[part 1 of 2: packages /EcuInstances to /Communication/TpConfig]
AUTOSAR XML (schema 4-2-2)
package /EcuInstances
  ecu instance IEM: associated-com-i-pdu-group=[TxMPG_PropulsionCAN, RxMPG_PropulsionCAN], com-configuration-gw-time-base=0.005, com-configuration-rx-time-base=0.005, com-configuration-tx-time-base=0.005, sleep-mode-supported=true, wake-up-over-bus-supported=true  # Inverter Electric rear axle drive Module
    can communication controller PropulsionCAN: wake-up-by-controller-supported=true, can-controller-attributes=can-controller-configuration-requirements={max-number-of-time-quanta-per-bit=22, max-sample-point=86.67, max-sync-jump-width=13, min-number-of-time-quanta-per-bit=10, min-sample-point=80, min-sync-jump-width=9}
    can communication connector PropulsionCAN_IEM: comm-controller=PropulsionCAN, pnc-gateway-type=NONE, pnc-wakeup-data-mask=594567823360
package /CommunicationClusters
  can cluster PropulsionCAN: baudrate=500000, protocol-name=CAN, protocol-version=CAN
    can physical channel PropulsionCAN: comm-connectors=PropulsionCAN_IEM
      frame IemToVddmPropDiagResFrame: id 0x637, from IEM, frame-length=8, can-addressing-mode=STANDARD, can-fd-frame-support=false, can-frame-tx-behavior=CAN-20
        n pdu IemToVddmPropDiagResNpdu: length=8
      frame IemPropNMFr: id 0x51C, from IEM, frame-length=8, can-addressing-mode=STANDARD, can-fd-frame-support=false, can-frame-tx-behavior=CAN-20
        nm pdu IemPropNmPdu1: length=8, nm-vote-information=false, unused-bit-pattern=0
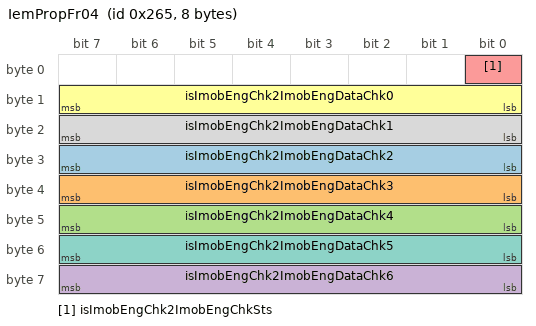
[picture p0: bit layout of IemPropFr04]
      frame IemPropFr04: id 0x265, from IEM, frame-length=8, can-addressing-mode=STANDARD, can-fd-frame-support=false, can-frame-tx-behavior=CAN-20
        pdu IemPropSignalIPdu04: length=8, transmission-mode-condition{data-filter=data-filter-type=ALWAYS, i-signal-in-i-pdu=isImobEngChk2ImobEngChkSts_mtx}, transmission-mode-true-timing=cyclic-timing={time-offset=0, time-period=0.08}, unused-bit-pattern=0
          signal isImobEngChk2ImobEngDataChk2: start 31, 8 bit, big-endian, data-type-policy=NETWORK-REPRESENTATION-FROM-COM-SPEC, init-value=0, base-type=UInt8_2, compu {identical; unit Unitless}, category=VALUE  # Message from IEM to CEM that challenge is available and 7 bytes of challenge. Byte 2
          signal isImobEngChk2ImobEngDataChk3: start 39, 8 bit, big-endian, data-type-policy=NETWORK-REPRESENTATION-FROM-COM-SPEC, init-value=0, base-type=UInt8_2, compu {identical; unit Unitless}, category=VALUE  # Message from IEM to CEM that challenge is available and 7 bytes of challenge. Byte 3
          signal isImobEngChk2ImobEngDataChk4: start 47, 8 bit, big-endian, data-type-policy=NETWORK-REPRESENTATION-FROM-COM-SPEC, init-value=0, base-type=UInt8_2, compu {identical; unit Unitless}, category=VALUE  # Message from IEM to CEM that challenge is available and 7 bytes of challenge. Byte 4
          signal isImobEngChk2ImobEngDataChk6: start 63, 8 bit, big-endian, data-type-policy=NETWORK-REPRESENTATION-FROM-COM-SPEC, init-value=0, base-type=UInt8_2, compu {identical; unit Unitless}, category=VALUE  # Message from IEM to CEM that challenge is available and 7 bytes of challenge. Byte 6
          signal isImobEngChk2ImobEngChkSts: start 0, 1 bit, big-endian, data-type-policy=NETWORK-REPRESENTATION-FROM-COM-SPEC, init-value=0, base-type=AvlSts2_2, compu {0=AvlSts2_NotAvl, 1=AvlSts2_Avl; unit Unitless}, category=VALUE  # Message from IEM to CEM that challenge is available and 7 bytes of challenge. Message to CEM Challenge available
          signal isImobEngChk2ImobEngDataChk0: start 15, 8 bit, big-endian, data-type-policy=NETWORK-REPRESENTATION-FROM-COM-SPEC, init-value=0, base-type=UInt8_2, compu {identical; unit Unitless}, category=VALUE  # Message from IEM to CEM that challenge is available and 7 bytes of challenge. Byte 0
          signal isImobEngChk2ImobEngDataChk5: start 55, 8 bit, big-endian, data-type-policy=NETWORK-REPRESENTATION-FROM-COM-SPEC, init-value=0, base-type=UInt8_2, compu {identical; unit Unitless}, category=VALUE  # Message from IEM to CEM that challenge is available and 7 bytes of challenge. Byte 5
          signal isImobEngChk2ImobEngDataChk1: start 23, 8 bit, big-endian, data-type-policy=NETWORK-REPRESENTATION-FROM-COM-SPEC, init-value=0, base-type=UInt8_2, compu {identical; unit Unitless}, category=VALUE  # Message from IEM to CEM that challenge is available and 7 bytes of challenge. Byte 1
          mapping igImobEngChk2_mtx: i-signal-group=igImobEngChk2, packing-byte-order=big-endian, start-position=0, transfer-property=PENDING, update-indication-bit-position=1
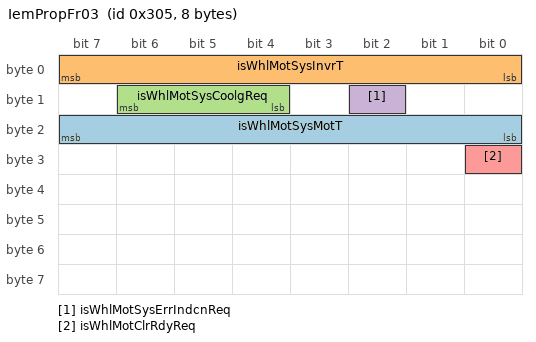
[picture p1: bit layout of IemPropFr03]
      frame IemPropFr03: id 0x305, from IEM, frame-length=8, can-addressing-mode=STANDARD, can-fd-frame-support=false, can-frame-tx-behavior=CAN-20
        pdu IemPropSignalIPdu03: length=8, transmission-mode-condition{data-filter=data-filter-type=ALWAYS, i-signal-in-i-pdu=isWhlMotSysInvrT_mtx}, transmission-mode-true-timing=cyclic-timing={time-offset=0, time-period=0.6}, unused-bit-pattern=0
          signal isWhlMotSysMotT: start 23, 8 bit, big-endian, data-type-policy=NETWORK-REPRESENTATION-FROM-COM-SPEC, init-value=50, base-type=T3_2, compu {phys=raw-50 for raw 0..250; unit degC}, transfer-property=PENDING, update-indication-bit-position=8  # The temperature of motor
          signal isWhlMotSysInvrT: start 7, 8 bit, big-endian, data-type-policy=NETWORK-REPRESENTATION-FROM-COM-SPEC, init-value=50, base-type=T3_2, compu {phys=raw-50 for raw 0..250; unit degC}, transfer-property=PENDING, update-indication-bit-position=15  # The inverter temperature measured in the IEM.
          signal isWhlMotSysCoolgReq: start 14, 3 bit, big-endian, data-type-policy=NETWORK-REPRESENTATION-FROM-COM-SPEC, init-value=0, base-type=HvCoolg1_2, compu-method=HvCoolg1_1, transfer-property=PENDING, update-indication-bit-position=11  # Signal to request increased cooling to Erad and IEM.Request is in 3 steps of increased cooling.
          signal isWhlMotSysErrIndcnReq: start 10, 1 bit, big-endian, data-type-policy=NETWORK-REPRESENTATION-FROM-COM-SPEC, init-value=0, base-type=OnOff1_2, compu {0=OnOff1_Off, 1=OnOff1_On; unit Unitless}, transfer-property=PENDING, update-indication-bit-position=9
          signal isWhlMotClrRdyReq: start 24, 1 bit, big-endian, data-type-policy=NETWORK-REPRESENTATION-FROM-COM-SPEC, init-value=0, base-type=OnOff1_2, compu {0=OnOff1_Off, 1=OnOff1_On; unit Unitless}, transfer-property=PENDING, update-indication-bit-position=25
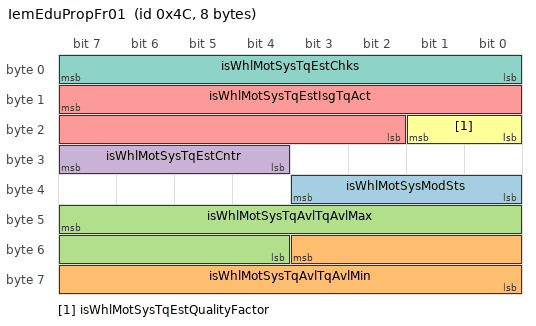
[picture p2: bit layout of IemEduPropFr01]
      frame IemEduPropFr01: id 0x4C, from IEM, frame-length=8, can-addressing-mode=STANDARD, can-fd-frame-support=false, can-frame-tx-behavior=CAN-20
        pdu IemEduPropSignalIPdu01: length=8, transmission-mode-condition{data-filter=data-filter-type=ALWAYS, i-signal-in-i-pdu=isWhlMotSysTqEstChks_mtx}, transmission-mode-true-timing=cyclic-timing={time-offset=0, time-period=0.01}, unused-bit-pattern=0
          signal isWhlMotSysModSts: start 35, 4 bit, big-endian, data-type-policy=NETWORK-REPRESENTATION-FROM-COM-SPEC, init-value=0, base-type=WhlMotSysModStsTyp2_2, compu-method=WhlMotSysModStsTyp2_2, transfer-property=PENDING, update-indication-bit-position=36  # Reflects the current operating mode of the IEM.
          signal isWhlMotSysTqAvlTqAvlMin: start 51, 12 bit, big-endian, data-type-policy=NETWORK-REPRESENTATION-FROM-COM-SPEC, init-value=2047, base-type=HvTq1_2, compu {phys=raw*4-8188 for raw 0..4095; unit NewtonMeter}, category=VALUE  # Min available torque
          signal isWhlMotSysTqAvlTqAvlMax: start 47, 12 bit, big-endian, data-type-policy=NETWORK-REPRESENTATION-FROM-COM-SPEC, init-value=2047, base-type=HvTq1_2, compu {phys=raw*4-8188 for raw 0..4095; unit NewtonMeter}, category=VALUE  # Max available torque
          mapping igWhlMotSysTqAvl_mtx: i-signal-group=igWhlMotSysTqAvl, packing-byte-order=big-endian, start-position=47, transfer-property=PENDING, update-indication-bit-position=37
          signal isWhlMotSysTqEstCntr: start 31, 4 bit, big-endian, data-type-policy=NETWORK-REPRESENTATION-FROM-COM-SPEC, init-value=0, base-type=UInt4_2, compu {identical; unit Unitless}, category=VALUE  # Counter of estimation torque
          signal isWhlMotSysTqEstIsgTqAct: start 15, 14 bit, big-endian, data-type-policy=NETWORK-REPRESENTATION-FROM-COM-SPEC, init-value=8188, base-type=Tq34_1, compu {phys=raw-8188 for raw 0..16380; unit NewtonMeter}, category=VALUE  # Estimation torque of Rear Axle Control
          signal isWhlMotSysTqEstQualityFactor: start 17, 2 bit, big-endian, data-type-policy=NETWORK-REPRESENTATION-FROM-COM-SPEC, init-value=1, base-type=QualityFactor_2, compu-method=QualityFactor_1, category=VALUE  # Quality factor of estimation torque
          signal isWhlMotSysTqEstChks: start 7, 8 bit, big-endian, data-type-policy=NETWORK-REPRESENTATION-FROM-COM-SPEC, init-value=0, base-type=UInt8_2, compu {identical; unit Unitless}, category=VALUE  # Checksum of estimation torque
          mapping igWhlMotSysTqEst_mtx: i-signal-group=igWhlMotSysTqEst, packing-byte-order=big-endian, start-position=7, transfer-property=PENDING, update-indication-bit-position=27
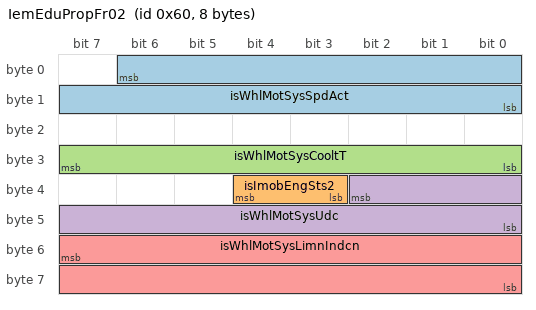
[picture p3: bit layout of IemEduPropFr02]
      frame IemEduPropFr02: id 0x60, from IEM, frame-length=8, can-addressing-mode=STANDARD, can-fd-frame-support=false, can-frame-tx-behavior=CAN-20
        pdu IemEduPropSignalIPdu02: length=8, transmission-mode-condition{data-filter=data-filter-type=ALWAYS, i-signal-in-i-pdu=isWhlMotSysSpdAct_mtx}, transmission-mode-true-timing=cyclic-timing={time-offset=0, time-period=0.02}, unused-bit-pattern=0
          signal isWhlMotSysSpdAct: start 6, 15 bit, big-endian, data-type-policy=NETWORK-REPRESENTATION-FROM-COM-SPEC, init-value=0, base-type=IsgSpdWSgnTyp_2, compu {phys=raw for raw -16384..16383; unit rpm}, transfer-property=PENDING, update-indication-bit-position=7  # The actual rotational speed of rear motor
          signal isImobEngSts2: start 36, 2 bit, big-endian, data-type-policy=NETWORK-REPRESENTATION-FROM-COM-SPEC, init-value=0, base-type=ImobSts_2, compu-method=ImobSts_1, transfer-property=PENDING, update-indication-bit-position=37  # IEM CEM message immo status. Can be undefined, immobilised, motive mobilised or non motive mobilised.
          signal isWhlMotSysCooltT: start 31, 8 bit, big-endian, data-type-policy=NETWORK-REPRESENTATION-FROM-COM-SPEC, init-value=40, base-type=HvT1_3, compu {phys=raw-40 for raw 0..255; unit degC}, transfer-property=PENDING, update-indication-bit-position=16  # Measured coolant temperature in rear axle inverter in degC
          signal isWhlMotSysUdc: start 34, 11 bit, big-endian, data-type-policy=NETWORK-REPRESENTATION-FROM-COM-SPEC, init-value=0, base-type=HvU1_2, compu {phys=raw*0.25 for raw 0..2044; unit Volt}, transfer-property=PENDING, update-indication-bit-position=38  # The DC voltage of rear motor
          signal isWhlMotSysLimnIndcn: start 55, 16 bit, big-endian, data-type-policy=NETWORK-REPRESENTATION-FROM-COM-SPEC, init-value=0, base-type=UInt16_2, compu {identical; unit Unitless}, transfer-property=PENDING, update-indication-bit-position=39  # The limitation indication of derating conditions
      frame IemToVgmJ1979OBDPropCanResFrame11: id 0x7EB, from IEM, frame-length=8, can-addressing-mode=STANDARD, can-fd-frame-support=false, can-frame-tx-behavior=CAN-20
        n pdu IemToVgmJ1979OBDPropCanResNpdu11: length=8
      frame UudtIemFr01: id 0x6F0, from IEM, frame-length=8, can-addressing-mode=STANDARD, can-fd-frame-support=false, can-frame-tx-behavior=CAN-20
        n pdu UudtIemNPdu1: length=8
      frame UudtIemFr02: id 0x6F1, from IEM, frame-length=8, can-addressing-mode=STANDARD, can-fd-frame-support=false, can-frame-tx-behavior=CAN-20
        n pdu UudtIemNPdu2: length=8
      frame UudtIemFr03: id 0x6F2, from IEM, frame-length=8, can-addressing-mode=STANDARD, can-fd-frame-support=false, can-frame-tx-behavior=CAN-20
        n pdu UudtIemNPdu3: length=8
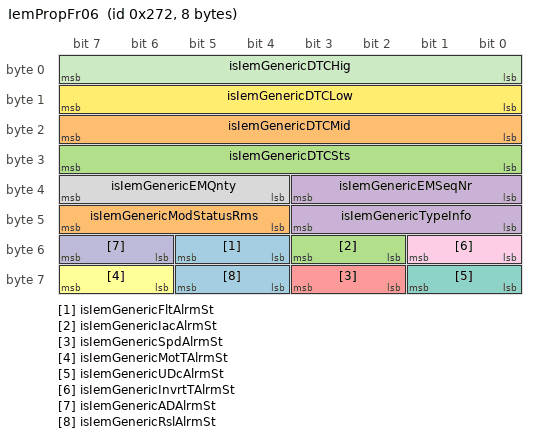
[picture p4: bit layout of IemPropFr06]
      frame IemPropFr06: id 0x272, from IEM, frame-length=8, can-addressing-mode=STANDARD, can-fd-frame-support=false, can-frame-tx-behavior=CAN-20
        pdu IemPropSignalIPdu06: length=8, transmission-mode-condition{data-filter=data-filter-type=ALWAYS, i-signal-in-i-pdu=isIemGenericDTCHig_mtx}, transmission-mode-true-timing=cyclic-timing={time-offset=0, time-period=0.1}, unused-bit-pattern=0
          signal isIemGenericFltAlrmSt: start 53, 2 bit, big-endian, data-type-policy=NETWORK-REPRESENTATION-FROM-COM-SPEC, init-value=0, base-type=AlrmSt_2, compu {0=AlrmSt_Disarmd, 1=AlrmSt_Armd, 2=AlrmSt_Actv; unit Unitless}, category=VALUE  # Fault alarm status
          signal isIemGenericModStatusRms: start 47, 4 bit, big-endian, data-type-policy=NETWORK-REPRESENTATION-FROM-COM-SPEC, init-value=3, base-type=ModStatusRms_2, compu-method=ModStatusRms_2, category=VALUE  # Motor status for RMS monitor
          signal isIemGenericIacAlrmSt: start 51, 2 bit, big-endian, data-type-policy=NETWORK-REPRESENTATION-FROM-COM-SPEC, init-value=0, base-type=AlrmSt_2, compu {0=AlrmSt_Disarmd, 1=AlrmSt_Armd, 2=AlrmSt_Actv; unit Unitless}, category=VALUE  # 3 Phase current alarm status
          signal isIemGenericEMSeqNr: start 35, 4 bit, big-endian, data-type-policy=NETWORK-REPRESENTATION-FROM-COM-SPEC, init-value=0, base-type=UInt4_2, compu {identical; unit Unitless}, category=VALUE  # Sequence number of electric motor
          signal isIemGenericSpdAlrmSt: start 59, 2 bit, big-endian, data-type-policy=NETWORK-REPRESENTATION-FROM-COM-SPEC, init-value=0, base-type=AlrmSt_2, compu {0=AlrmSt_Disarmd, 1=AlrmSt_Armd, 2=AlrmSt_Actv; unit Unitless}, category=VALUE  # Over speed alarm status
          signal isIemGenericMotTAlrmSt: start 63, 2 bit, big-endian, data-type-policy=NETWORK-REPRESENTATION-FROM-COM-SPEC, init-value=0, base-type=AlrmSt_2, compu {0=AlrmSt_Disarmd, 1=AlrmSt_Armd, 2=AlrmSt_Actv; unit Unitless}, category=VALUE  # Motor temperature alarm status
          signal isIemGenericUDcAlrmSt: start 57, 2 bit, big-endian, data-type-policy=NETWORK-REPRESENTATION-FROM-COM-SPEC, init-value=0, base-type=AlrmSt_2, compu {0=AlrmSt_Disarmd, 1=AlrmSt_Armd, 2=AlrmSt_Actv; unit Unitless}, category=VALUE  # High voltage alarm status
          signal isIemGenericEMQnty: start 39, 4 bit, big-endian, data-type-policy=NETWORK-REPRESENTATION-FROM-COM-SPEC, init-value=0, base-type=UInt4_2, compu {identical; unit Unitless}, category=VALUE  # Quantity of electric motor
          signal isIemGenericInvrtTAlrmSt: start 49, 2 bit, big-endian, data-type-policy=NETWORK-REPRESENTATION-FROM-COM-SPEC, init-value=0, base-type=AlrmSt_2, compu {0=AlrmSt_Disarmd, 1=AlrmSt_Armd, 2=AlrmSt_Actv; unit Unitless}, category=VALUE  # Inverter temperature alarm status
          signal isIemGenericADAlrmSt: start 55, 2 bit, big-endian, data-type-policy=NETWORK-REPRESENTATION-FROM-COM-SPEC, init-value=0, base-type=AlrmSt_2, compu {0=AlrmSt_Disarmd, 1=AlrmSt_Armd, 2=AlrmSt_Actv; unit Unitless}, category=VALUE  # Active Discharge fault alarm status
          signal isIemGenericDTCHig: start 7, 8 bit, big-endian, data-type-policy=NETWORK-REPRESENTATION-FROM-COM-SPEC, init-value=0, base-type=UInt8_2, compu {identical; unit Unitless}, category=VALUE  # DTC high byte for non OBD or OBD
          signal isIemGenericDTCLow: start 15, 8 bit, big-endian, data-type-policy=NETWORK-REPRESENTATION-FROM-COM-SPEC, init-value=0, base-type=UInt8_2, compu {identical; unit Unitless}, category=VALUE  # DTC low byte for non OBD
          signal isIemGenericRslAlrmSt: start 61, 2 bit, big-endian, data-type-policy=NETWORK-REPRESENTATION-FROM-COM-SPEC, init-value=0, base-type=AlrmSt_2, compu {0=AlrmSt_Disarmd, 1=AlrmSt_Armd, 2=AlrmSt_Actv; unit Unitless}, category=VALUE  # Resolver fault alarm status
          signal isIemGenericDTCMid: start 23, 8 bit, big-endian, data-type-policy=NETWORK-REPRESENTATION-FROM-COM-SPEC, init-value=0, base-type=UInt8_2, compu {identical; unit Unitless}, category=VALUE  # DTC middle byte for non OBD DTC low byte for OBD
          signal isIemGenericDTCSts: start 31, 8 bit, big-endian, data-type-policy=NETWORK-REPRESENTATION-FROM-COM-SPEC, init-value=0, base-type=UInt8_2, compu {identical; unit Unitless}, category=VALUE  # DTC Status
          signal isIemGenericTypeInfo: start 43, 4 bit, big-endian, data-type-policy=NETWORK-REPRESENTATION-FROM-COM-SPEC, init-value=0, base-type=UInt4_2, compu {identical; unit Unitless}, category=VALUE  # Indicate different EDS suppliers. OEM defines this value. 0=not defined 1=PMA1 VseA, with ratio=10.134 2=PMA1 Nidec,with ratio=10.294 3=PMA1 VREMT,with ratio=11.56 4=SPAL Scheaffler,with ratio=9.071 5=SPA Simens, with ratio=10.008 6=PMA2 VREMT,with ratio=11.209 7=EPA ZF,with radio=9.187 8=EPA Polestar,with 2-gear ratio=7.155 and 13.645 9=PMA2 UAES,with ratio=11.067
          mapping igIemGeneric_mtx: i-signal-group=igIemGeneric, packing-byte-order=big-endian, start-position=7, transfer-property=PENDING
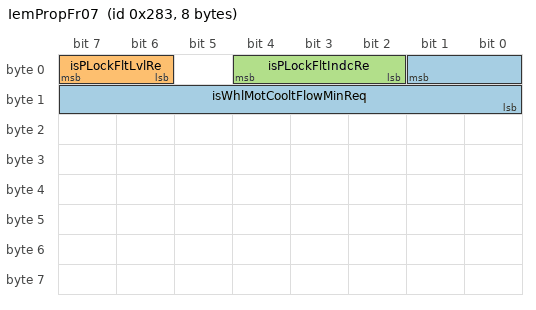
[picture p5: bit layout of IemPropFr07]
      frame IemPropFr07: id 0x283, from IEM, frame-length=8, can-addressing-mode=STANDARD, can-fd-frame-support=false, can-frame-tx-behavior=CAN-20
        pdu IemPropSignalIPdu07: length=8, transmission-mode-condition{data-filter=data-filter-type=ALWAYS, i-signal-in-i-pdu=isWhlMotCooltFlowMinReq_mtx}, transmission-mode-true-timing=cyclic-timing={time-offset=0, time-period=0.15}, unused-bit-pattern=0
          signal isWhlMotCooltFlowMinReq: start 1, 10 bit, big-endian, data-type-policy=NETWORK-REPRESENTATION-FROM-COM-SPEC, init-value=0, base-type=CooltFlowForDtElec1_2, compu {phys=raw*0.01 for raw 0..1023; unit L / min}, transfer-property=PENDING, update-indication-bit-position=54  # Minimum coolant flow required by rear wheel motor
          signal isPLockFltLvlRe: start 7, 2 bit, big-endian, data-type-policy=NETWORK-REPRESENTATION-FROM-COM-SPEC, init-value=0, base-type=FltLvl_1, compu {0=FltLvl_NoFlt, 1=FltLvl_FltLvl1, 2=FltLvl_FltLvl2; unit Unitless}, transfer-property=PENDING, update-indication-bit-position=55  # P-lock fault level, for rear electric drive.
          signal isPLockFltIndcRe: start 4, 3 bit, big-endian, data-type-policy=NETWORK-REPRESENTATION-FROM-COM-SPEC, init-value=0, base-type=FltIndcn_1, compu-method=FltIndcn_1, transfer-property=PENDING, update-indication-bit-position=5  # Fault indication signal for P-lock, for rear electric drive
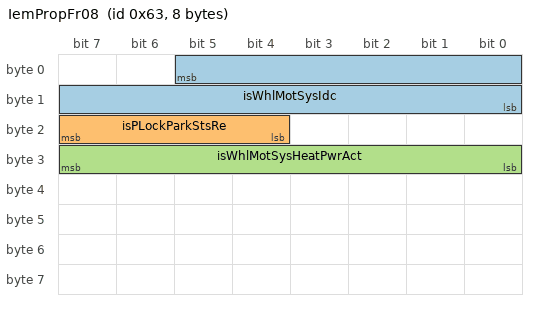
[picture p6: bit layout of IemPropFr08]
      frame IemPropFr08: id 0x63, from IEM, frame-length=8, can-addressing-mode=STANDARD, can-fd-frame-support=false, can-frame-tx-behavior=CAN-20
        pdu IemPropSignalIPdu08: length=8, transmission-mode-condition{data-filter=data-filter-type=ALWAYS, i-signal-in-i-pdu=isWhlMotSysIdc_mtx}, transmission-mode-true-timing=cyclic-timing={time-offset=0, time-period=0.02}, unused-bit-pattern=0
          signal isWhlMotSysIdc: start 5, 14 bit, big-endian, data-type-policy=NETWORK-REPRESENTATION-FROM-COM-SPEC, init-value=8188, base-type=Ampr1_1, compu {phys=raw*0.1-818.8 for raw 0..16380; unit A}, transfer-property=PENDING, update-indication-bit-position=6  # DC current measured in the IEM.
          signal isPLockParkStsRe: start 23, 4 bit, big-endian, data-type-policy=NETWORK-REPRESENTATION-FROM-COM-SPEC, init-value=7, base-type=ParkSts_1, compu-method=ParkSts_1, transfer-property=PENDING, update-indication-bit-position=7  # P-lock status (IEM)
          signal isWhlMotSysHeatPwrAct: start 31, 8 bit, big-endian, data-type-policy=NETWORK-REPRESENTATION-FROM-COM-SPEC, init-value=0, base-type=IsgHeatPwr_1, compu {phys=raw*50 for raw 0..255; unit W}, transfer-property=PENDING, update-indication-bit-position=19  # The actual electrical energy consumption for active heating of rear motor
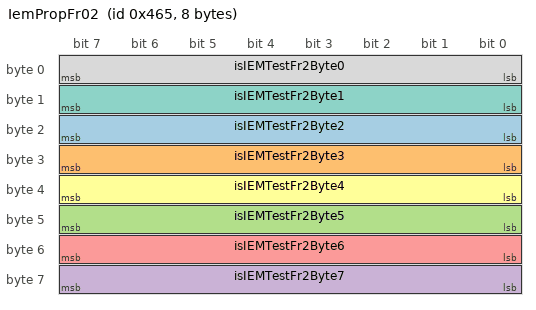
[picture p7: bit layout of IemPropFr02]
      frame IemPropFr02: id 0x465, from IEM, frame-length=8, can-addressing-mode=STANDARD, can-fd-frame-support=false, can-frame-tx-behavior=CAN-20
        pdu IemPropSignalIPdu02: length=8, transmission-mode-condition{data-filter=data-filter-type=ALWAYS, i-signal-in-i-pdu=isIEMTestFr2Byte0_mtx}, transmission-mode-true-timing=cyclic-timing={time-offset=0, time-period=0.8}, unused-bit-pattern=0
          signal isIEMTestFr2Byte2: start 23, 8 bit, big-endian, data-type-policy=NETWORK-REPRESENTATION-FROM-COM-SPEC, init-value=0, base-type=UInt8_2, compu {identical; unit Unitless}, category=VALUE  # DTC1 middle byte
          signal isIEMTestFr2Byte3: start 31, 8 bit, big-endian, data-type-policy=NETWORK-REPRESENTATION-FROM-COM-SPEC, init-value=0, base-type=UInt8_2, compu {identical; unit Unitless}, category=VALUE  # DTC1 high byte
          signal isIEMTestFr2Byte5: start 47, 8 bit, big-endian, data-type-policy=NETWORK-REPRESENTATION-FROM-COM-SPEC, init-value=0, base-type=UInt8_2, compu {identical; unit Unitless}, category=VALUE  # DTC2 low byte
          signal isIEMTestFr2Byte7: start 63, 8 bit, big-endian, data-type-policy=NETWORK-REPRESENTATION-FROM-COM-SPEC, init-value=0, base-type=UInt8_2, compu {identical; unit Unitless}, category=VALUE  # DTC2 high byte
          signal isIEMTestFr2Byte6: start 55, 8 bit, big-endian, data-type-policy=NETWORK-REPRESENTATION-FROM-COM-SPEC, init-value=0, base-type=UInt8_2, compu {identical; unit Unitless}, category=VALUE  # DTC2 middle byte
          signal isIEMTestFr2Byte4: start 39, 8 bit, big-endian, data-type-policy=NETWORK-REPRESENTATION-FROM-COM-SPEC, init-value=0, base-type=UInt8_2, compu {identical; unit Unitless}, category=VALUE  # DTC2 status
          signal isIEMTestFr2Byte1: start 15, 8 bit, big-endian, data-type-policy=NETWORK-REPRESENTATION-FROM-COM-SPEC, init-value=0, base-type=UInt8_2, compu {identical; unit Unitless}, category=VALUE  # DTC1 low byte
          signal isIEMTestFr2Byte0: start 7, 8 bit, big-endian, data-type-policy=NETWORK-REPRESENTATION-FROM-COM-SPEC, init-value=0, base-type=UInt8_2, compu {identical; unit Unitless}, category=VALUE  # DTC1 status
          mapping igIEMTestFr2_mtx: i-signal-group=igIEMTestFr2, packing-byte-order=big-endian, start-position=7, transfer-property=TRIGGERED
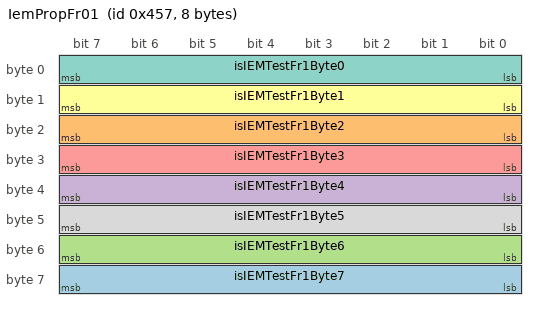
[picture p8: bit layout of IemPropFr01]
      frame IemPropFr01: id 0x457, from IEM, frame-length=8, can-addressing-mode=STANDARD, can-fd-frame-support=false, can-frame-tx-behavior=CAN-20
        pdu IemPropSignalIPdu01: length=8, transmission-mode-condition{data-filter=data-filter-type=ALWAYS, i-signal-in-i-pdu=isIEMTestFr1Byte0_mtx}, transmission-mode-true-timing=cyclic-timing={time-offset=0, time-period=0.8}, unused-bit-pattern=0
          signal isIEMTestFr1Byte7: start 63, 8 bit, big-endian, data-type-policy=NETWORK-REPRESENTATION-FROM-COM-SPEC, init-value=0, base-type=UInt8_2, compu {identical; unit Unitless}, category=VALUE  # DTC2 high byte
          signal isIEMTestFr1Byte2: start 23, 8 bit, big-endian, data-type-policy=NETWORK-REPRESENTATION-FROM-COM-SPEC, init-value=0, base-type=UInt8_2, compu {identical; unit Unitless}, category=VALUE  # DTC1 middle byte
          signal isIEMTestFr1Byte6: start 55, 8 bit, big-endian, data-type-policy=NETWORK-REPRESENTATION-FROM-COM-SPEC, init-value=0, base-type=UInt8_2, compu {identical; unit Unitless}, category=VALUE  # DTC2 middle byte
          signal isIEMTestFr1Byte4: start 39, 8 bit, big-endian, data-type-policy=NETWORK-REPRESENTATION-FROM-COM-SPEC, init-value=0, base-type=UInt8_2, compu {identical; unit Unitless}, category=VALUE  # DTC2 status
          signal isIEMTestFr1Byte3: start 31, 8 bit, big-endian, data-type-policy=NETWORK-REPRESENTATION-FROM-COM-SPEC, init-value=0, base-type=UInt8_2, compu {identical; unit Unitless}, category=VALUE  # DTC1 high byte
          signal isIEMTestFr1Byte1: start 15, 8 bit, big-endian, data-type-policy=NETWORK-REPRESENTATION-FROM-COM-SPEC, init-value=0, base-type=UInt8_2, compu {identical; unit Unitless}, category=VALUE  # DTC1 low byte
          signal isIEMTestFr1Byte0: start 7, 8 bit, big-endian, data-type-policy=NETWORK-REPRESENTATION-FROM-COM-SPEC, init-value=0, base-type=UInt8_2, compu {identical; unit Unitless}, category=VALUE  # DTC1 status
          signal isIEMTestFr1Byte5: start 47, 8 bit, big-endian, data-type-policy=NETWORK-REPRESENTATION-FROM-COM-SPEC, init-value=0, base-type=UInt8_2, compu {identical; unit Unitless}, category=VALUE  # DTC2 low byte
          mapping igIEMTestFr1_mtx: i-signal-group=igIEMTestFr1, packing-byte-order=big-endian, start-position=7, transfer-property=TRIGGERED
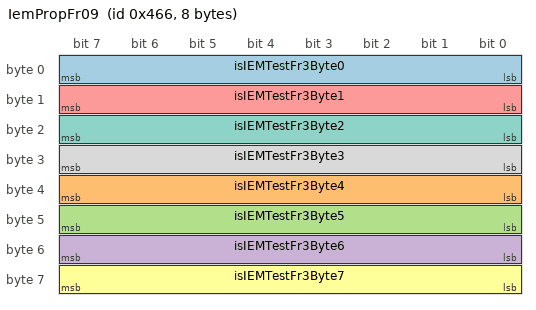
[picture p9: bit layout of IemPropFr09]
      frame IemPropFr09: id 0x466, from IEM, frame-length=8, can-addressing-mode=STANDARD, can-fd-frame-support=false, can-frame-tx-behavior=CAN-20
        pdu IemPropSignalIPdu09: length=8, transmission-mode-condition{data-filter=data-filter-type=ALWAYS, i-signal-in-i-pdu=isIEMTestFr3Byte0_mtx}, transmission-mode-true-timing=cyclic-timing={time-offset=0, time-period=0.8}, unused-bit-pattern=0
          signal isIEMTestFr3Byte0: start 7, 8 bit, big-endian, data-type-policy=NETWORK-REPRESENTATION-FROM-COM-SPEC, init-value=0, base-type=UInt8_2, compu {identical; unit Unitless}, category=VALUE  # Info0
          signal isIEMTestFr3Byte4: start 39, 8 bit, big-endian, data-type-policy=NETWORK-REPRESENTATION-FROM-COM-SPEC, init-value=0, base-type=UInt8_2, compu {identical; unit Unitless}, category=VALUE  # Info4
          signal isIEMTestFr3Byte5: start 47, 8 bit, big-endian, data-type-policy=NETWORK-REPRESENTATION-FROM-COM-SPEC, init-value=0, base-type=UInt8_2, compu {identical; unit Unitless}, category=VALUE  # Info5
          signal isIEMTestFr3Byte6: start 55, 8 bit, big-endian, data-type-policy=NETWORK-REPRESENTATION-FROM-COM-SPEC, init-value=0, base-type=UInt8_2, compu {identical; unit Unitless}, category=VALUE  # Info6
          signal isIEMTestFr3Byte1: start 15, 8 bit, big-endian, data-type-policy=NETWORK-REPRESENTATION-FROM-COM-SPEC, init-value=0, base-type=UInt8_2, compu {identical; unit Unitless}, category=VALUE  # Info1
          signal isIEMTestFr3Byte7: start 63, 8 bit, big-endian, data-type-policy=NETWORK-REPRESENTATION-FROM-COM-SPEC, init-value=0, base-type=UInt8_2, compu {identical; unit Unitless}, category=VALUE  # Info7
          signal isIEMTestFr3Byte2: start 23, 8 bit, big-endian, data-type-policy=NETWORK-REPRESENTATION-FROM-COM-SPEC, init-value=0, base-type=UInt8_2, compu {identical; unit Unitless}, category=VALUE  # Info2
          signal isIEMTestFr3Byte3: start 31, 8 bit, big-endian, data-type-policy=NETWORK-REPRESENTATION-FROM-COM-SPEC, init-value=0, base-type=UInt8_2, compu {identical; unit Unitless}, category=VALUE  # Info3
          mapping igIEMTestFr3_mtx: i-signal-group=igIEMTestFr3, packing-byte-order=big-endian, start-position=7, transfer-property=TRIGGERED
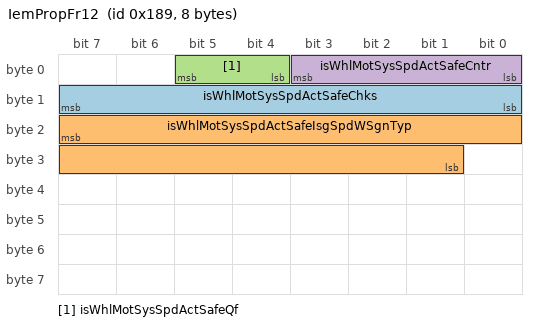
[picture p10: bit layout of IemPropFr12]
      frame IemPropFr12: id 0x189, from IEM, frame-length=8, can-addressing-mode=STANDARD, can-fd-frame-support=false, can-frame-tx-behavior=CAN-20
        pdu IemPropSignalIPdu12: length=8, transmission-mode-condition{data-filter=data-filter-type=ALWAYS, i-signal-in-i-pdu=isWhlMotSysSpdActSafeCntr_mtx}, transmission-mode-true-timing=cyclic-timing={time-offset=0, time-period=0.04}, unused-bit-pattern=0
          signal isWhlMotSysSpdActSafeChks: start 15, 8 bit, big-endian, data-type-policy=NETWORK-REPRESENTATION-FROM-COM-SPEC, init-value=0, base-type=UInt8_2, compu {identical; unit Unitless}, category=VALUE  # checksum
          signal isWhlMotSysSpdActSafeIsgSpdWSgnTyp: start 23, 15 bit, big-endian, data-type-policy=NETWORK-REPRESENTATION-FROM-COM-SPEC, init-value=0, base-type=IsgSpdWSgnTyp_2, compu {phys=raw for raw -16384..16383; unit rpm}, category=VALUE  # Safe EM motor shaft speed.
          signal isWhlMotSysSpdActSafeQf: start 5, 2 bit, big-endian, data-type-policy=NETWORK-REPRESENTATION-FROM-COM-SPEC, init-value=1, base-type=GenQf1_2, compu-method=GenQf1_1, category=VALUE  # quality factor
          signal isWhlMotSysSpdActSafeCntr: start 3, 4 bit, big-endian, data-type-policy=NETWORK-REPRESENTATION-FROM-COM-SPEC, init-value=0, base-type=UInt4_2, compu {identical; unit Unitless}, category=VALUE  # counter
          mapping igWhlMotSysSpdActSafe_mtx: i-signal-group=igWhlMotSysSpdActSafe, packing-byte-order=big-endian, start-position=3, transfer-property=PENDING, update-indication-bit-position=24
      frame IemPropFr14: id 0x220, from IEM, frame-length=8, can-addressing-mode=STANDARD, can-fd-frame-support=false, can-frame-tx-behavior=CAN-20
        pdu IemPropSignalIPdu14: length=8, transmission-mode-condition{data-filter=data-filter-type=ALWAYS, i-signal-in-i-pdu=isWhlMotSysHeatPwrMax_mtx}, transmission-mode-true-timing=cyclic-timing={time-offset=0, time-period=0.08}, unused-bit-pattern=0
          signal isWhlMotSysHeatPwrMax: start 7, 8 bit, big-endian, data-type-policy=NETWORK-REPRESENTATION-FROM-COM-SPEC, init-value=0, base-type=IsgHeatPwr_1, compu {phys=raw*50 for raw 0..255; unit W}, transfer-property=PENDING, update-indication-bit-position=12  # The electrical power required by the current maximum heating power of the rear motor
          signal isWhlMotSysHeatFdBck: start 15, 2 bit, big-endian, data-type-policy=NETWORK-REPRESENTATION-FROM-COM-SPEC, init-value=1, base-type=WhlMotSysHeatFdBck_1, compu-method=WhlMotSysHeatFdBck_1, transfer-property=PENDING, update-indication-bit-position=13  # The feedback of the rear motor to responds to the heating enabling signal of ECM
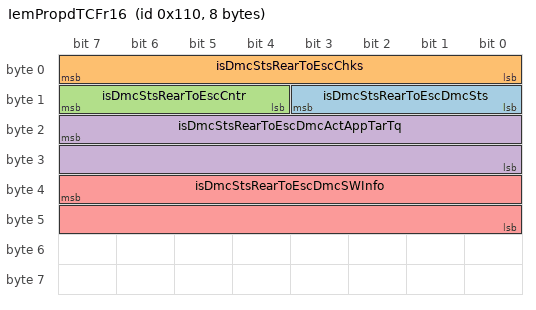
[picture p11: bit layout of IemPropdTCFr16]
      frame IemPropdTCFr16: id 0x110, from IEM, frame-length=8, can-addressing-mode=STANDARD, can-fd-frame-support=false, can-frame-tx-behavior=CAN-20
        pdu IemPropSignalIPdu16: length=8, transmission-mode-condition{data-filter=data-filter-type=ALWAYS, i-signal-in-i-pdu=isDmcStsRearToEscChks_mtx}, transmission-mode-true-timing=cyclic-timing={time-offset=0, time-period=0.02}, unused-bit-pattern=0
          signal isDmcStsRearToEscDmcSts: start 11, 4 bit, big-endian, data-type-policy=NETWORK-REPRESENTATION-FROM-COM-SPEC, init-value=0, base-type=DMC_1, compu {0=DMC_Init, 1=DMC_On, 2=DMC_Off, 3=DMC_Fault; unit Unitless}, category=VALUE
          signal isDmcStsRearToEscChks: start 7, 8 bit, big-endian, data-type-policy=NETWORK-REPRESENTATION-FROM-COM-SPEC, init-value=0, base-type=UInt8_2, compu {identical; unit Unitless}, category=VALUE  # Chks
          signal isDmcStsRearToEscCntr: start 15, 4 bit, big-endian, data-type-policy=NETWORK-REPRESENTATION-FROM-COM-SPEC, init-value=0, base-type=UInt4_2, compu {identical; unit Unitless}, category=VALUE  # Cntr
          signal isDmcStsRearToEscDmcActAppTarTq: start 23, 16 bit, big-endian, data-type-policy=NETWORK-REPRESENTATION-FROM-COM-SPEC, init-value=0, base-type=Tq35_1, compu {phys=raw for raw -30000..30000; unit NewtonMeter}, category=VALUE  # DMCActAppTarTq
          signal isDmcStsRearToEscDmcSWInfo: start 39, 16 bit, big-endian, data-type-policy=NETWORK-REPRESENTATION-FROM-COM-SPEC, init-value=0, base-type=UInt16_2, compu {identical; unit Unitless}, category=VALUE  # DmCSWinformation
          mapping igDmcStsRearToEsc_mtx: i-signal-group=igDmcStsRearToEsc, packing-byte-order=big-endian, start-position=7, transfer-property=PENDING, update-indication-bit-position=56
      frame VddmToAllFuncPropDiagReqFrame: id 0x7FF, to IEM, frame-length=8, can-addressing-mode=STANDARD, can-fd-frame-support=false, can-frame-rx-behavior=CAN-20
        n pdu VddmToAllFuncPropDiagReqNpdu: length=8
      frame VddmToIemPropDiagReqFrame: id 0x737, to IEM, frame-length=8, can-addressing-mode=STANDARD, can-fd-frame-support=false, can-frame-rx-behavior=CAN-20
        n pdu VddmToIemPropDiagReqNpdu: length=8
      frame VgmToIemJ1979OBDPropCanReqFrame11: id 0x7E3, to IEM, frame-length=8, can-addressing-mode=STANDARD, can-fd-frame-support=false, can-frame-rx-behavior=CAN-20
        n pdu VgmToIemJ1979OBDPropCanReqNpdu11: length=8
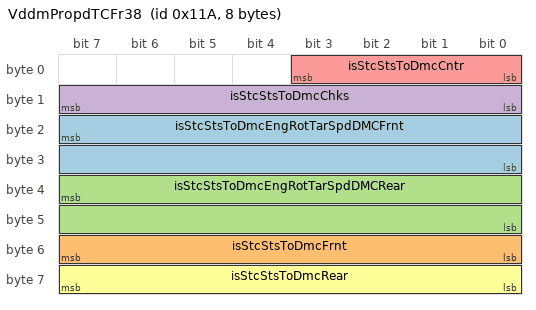
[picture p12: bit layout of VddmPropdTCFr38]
      frame VddmPropdTCFr38: id 0x11A, to IEM, frame-length=8, can-addressing-mode=STANDARD, can-fd-frame-support=false, can-frame-rx-behavior=CAN-20
        pdu VDDMPropdTCSignalIPdu38: length=8, unused-bit-pattern=0
          signal isStcStsToDmcEngRotTarSpdDMCFrnt: start 23, 16 bit, big-endian, data-type-policy=NETWORK-REPRESENTATION-FROM-COM-SPEC, init-value=0, base-type=UInt16_2, compu {identical; unit Unitless}, category=VALUE, to IEM  # EngRoTarSpdDMC frint
          signal isStcStsToDmcFrnt: start 55, 8 bit, big-endian, data-type-policy=NETWORK-REPRESENTATION-FROM-COM-SPEC, init-value=0, base-type=ModeDMC_1, compu {0=ModeDMC_Off, 1=ModeDMC_Rpm, 2=ModeDMC_Trq; unit Unitless}, category=VALUE, to IEM  # StcSts to Dmc frint
          signal isStcStsToDmcEngRotTarSpdDMCRear: start 39, 16 bit, big-endian, data-type-policy=NETWORK-REPRESENTATION-FROM-COM-SPEC, init-value=0, base-type=UInt16_2, compu {identical; unit Unitless}, category=VALUE, to IEM  # EngRoTarSpdDMC rear
          signal isStcStsToDmcChks: start 15, 8 bit, big-endian, data-type-policy=NETWORK-REPRESENTATION-FROM-COM-SPEC, init-value=0, base-type=UInt8_2, compu {identical; unit Unitless}, category=VALUE, to IEM  # Chks
          signal isStcStsToDmcCntr: start 3, 4 bit, big-endian, data-type-policy=NETWORK-REPRESENTATION-FROM-COM-SPEC, init-value=0, base-type=UInt4_2, compu {identical; unit Unitless}, category=VALUE, to IEM  # Cntr
          signal isStcStsToDmcRear: start 63, 8 bit, big-endian, data-type-policy=NETWORK-REPRESENTATION-FROM-COM-SPEC, init-value=0, base-type=ModeDMC_1, compu {0=ModeDMC_Off, 1=ModeDMC_Rpm, 2=ModeDMC_Trq; unit Unitless}, category=VALUE, to IEM  # StcSts to DMC Rear
          mapping igStcStsToDmc_mrx: i-signal-group=igStcStsToDmc, packing-byte-order=big-endian, start-position=3, update-indication-bit-position=4
      frame IgmPropNMFr: id 0x51B, to IEM, frame-length=8, can-addressing-mode=STANDARD, can-fd-frame-support=false, can-frame-rx-behavior=CAN-20, rx-identifier-range={lower-can-id=1280, upper-can-id=1343}
        nm pdu IgmPropNmPdu1: length=8, nm-vote-information=false, unused-bit-pattern=0
      frame EcmPropFr25: id 0x27A, to IEM, frame-length=8, can-addressing-mode=STANDARD, can-fd-frame-support=false, can-frame-rx-behavior=CAN-20
        pdu EcmPropSignalIPdu25: length=8, unused-bit-pattern=0
          signal isDrvgCyc: start 5, 1 bit, big-endian, data-type-policy=NETWORK-REPRESENTATION-FROM-COM-SPEC, init-value=0, base-type=OnOff1_2, compu {0=OnOff1_Off, 1=OnOff1_On; unit Unitless}, update-indication-bit-position=4, to IEM  # Transition from 0 to 1 indicates a start of a new Driving Cycle.
      frame VgmToAllJ1979OBDPropCanReqFrame11: id 0x7DF, to IEM, frame-length=8, can-addressing-mode=STANDARD, can-fd-frame-support=false, can-frame-rx-behavior=CAN-20
        n pdu VgmToAllFuncJ1979OBDPropCanReqNpdu11: length=8
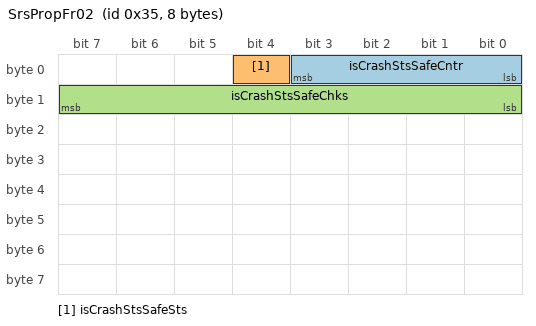
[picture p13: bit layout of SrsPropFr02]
      frame SrsPropFr02: id 0x35, to IEM, frame-length=8, can-addressing-mode=STANDARD, can-fd-frame-support=false, can-frame-rx-behavior=CAN-20
        pdu SrsPropSignalIPdu02: length=8, unused-bit-pattern=0
          signal isCrashStsSafeCntr: start 3, 4 bit, big-endian, data-type-policy=NETWORK-REPRESENTATION-FROM-COM-SPEC, init-value=0, base-type=UInt4_2, compu {identical; unit Unitless}, category=VALUE, to IEM  # Counter for E2E
          signal isCrashStsSafeSts: start 4, 1 bit, big-endian, data-type-policy=NETWORK-REPRESENTATION-FROM-COM-SPEC, init-value=0, base-type=CrashSts2_2, compu {0=CrashSts2_NoCrash, 1=CrashSts2_Crash; unit Unitless}, category=VALUE, to IEM  # Information if a crash has been detected by SRS.
          signal isCrashStsSafeChks: start 15, 8 bit, big-endian, data-type-policy=NETWORK-REPRESENTATION-FROM-COM-SPEC, init-value=255, base-type=UInt8_2, compu {identical; unit Unitless}, category=VALUE, to IEM  # Checksum for E2E
          mapping igCrashStsSafe_mrx: i-signal-group=igCrashStsSafe, packing-byte-order=big-endian, start-position=3, update-indication-bit-position=5
      frame VddmPropFr11: id 0x139, to IEM, frame-length=8, can-addressing-mode=STANDARD, can-fd-frame-support=false, can-frame-rx-behavior=CAN-20
        pdu VDDMPropSignalIPDU11: length=8, unused-bit-pattern=0
          signal isSpdRotlForWhlsAtAxleRe: start 38, 15 bit, big-endian, data-type-policy=NETWORK-REPRESENTATION-FROM-COM-SPEC, init-value=0, base-type=N1_2, compu {phys=raw*0.5 for raw 0..32767; unit rpm}, update-indication-bit-position=39, to IEM  # Average angular velocity of rear wheels.
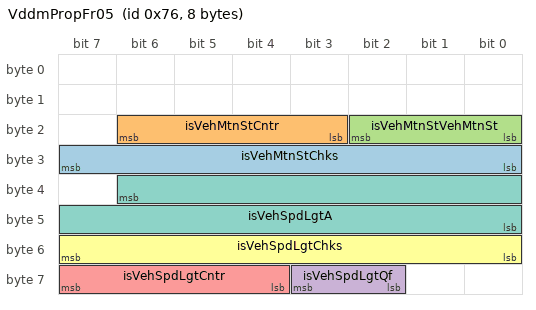
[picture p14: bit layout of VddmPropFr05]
      frame VddmPropFr05: id 0x76, to IEM, frame-length=8, can-addressing-mode=STANDARD, can-fd-frame-support=false, can-frame-rx-behavior=CAN-20
        pdu VDDMPropSignalIPDU05: length=8, unused-bit-pattern=0
          signal isVehMtnStChks: start 31, 8 bit, big-endian, data-type-policy=NETWORK-REPRESENTATION-FROM-COM-SPEC, init-value=0, base-type=UInt8_2, compu {identical; unit Unitless}, category=VALUE, to IEM  # Vehicle motion state information based on wheel speed sensors. Provides information about vehicle stand still and vehicle rolling direction. Checksum for vehicle motion state
          signal isVehMtnStCntr: start 22, 4 bit, big-endian, data-type-policy=NETWORK-REPRESENTATION-FROM-COM-SPEC, init-value=0, base-type=UInt4_2, compu {identical; unit Unitless}, category=VALUE, to IEM  # Vehicle motion state information based on wheel speed sensors. Provides information about vehicle stand still and vehicle rolling direction. Counter for vehicle motion state
          signal isVehMtnStVehMtnSt: start 18, 3 bit, big-endian, data-type-policy=NETWORK-REPRESENTATION-FROM-COM-SPEC, init-value=0, base-type=VehMtnSt2_2, compu-method=VehMtnSt2_1, category=VALUE, to IEM  # Vehicle motion state information based on wheel speed sensors. Provides information about vehicle stand still and vehicle rolling direction. Vehicle motion state
          mapping igVehMtnSt_mrx: i-signal-group=igVehMtnSt, packing-byte-order=big-endian, start-position=18, update-indication-bit-position=57
          signal isVehSpdLgtQf: start 59, 2 bit, big-endian, data-type-policy=NETWORK-REPRESENTATION-FROM-COM-SPEC, init-value=1, base-type=GenQf1_2, compu-method=GenQf1_1, category=VALUE, to IEM  # Quality factor for vehicle speed as measured by wheel speed sensors and longitudinal acceleration.
          signal isVehSpdLgtCntr: start 63, 4 bit, big-endian, data-type-policy=NETWORK-REPRESENTATION-FROM-COM-SPEC, init-value=0, base-type=UInt4_2, compu {identical; unit Unitless}, category=VALUE, to IEM  # Counter
          signal isVehSpdLgtChks: start 55, 8 bit, big-endian, data-type-policy=NETWORK-REPRESENTATION-FROM-COM-SPEC, init-value=0, base-type=UInt8_2, compu {identical; unit Unitless}, category=VALUE, to IEM  # Checksum
          signal isVehSpdLgtA: start 38, 15 bit, big-endian, data-type-policy=NETWORK-REPRESENTATION-FROM-COM-SPEC, init-value=0, base-type=Spd1_2, compu {phys=raw*0.00391 for raw 0..31970; unit m/s}, category=VALUE, to IEM  # Vehicle speed longitudinal based on wheel speed sensors and longitudinal acceleration.
          mapping igVehSpdLgt_mrx: i-signal-group=igVehSpdLgt, packing-byte-order=big-endian, start-position=38, update-indication-bit-position=39
      frame EcmPropFr04: id 0x131, to IEM, frame-length=8, can-addressing-mode=STANDARD, can-fd-frame-support=false, can-frame-rx-behavior=CAN-20
        pdu ECMPropSignalIPDU04: length=8, unused-bit-pattern=0
          signal isWhlMotSysPwrLimMax: start 41, 10 bit, big-endian, data-type-policy=NETWORK-REPRESENTATION-FROM-COM-SPEC, init-value=0, base-type=PrpsnPwrLimMax_2, compu {phys=raw*0.5 for raw 0..1022; unit kW}, update-indication-bit-position=45, to IEM  # Maximum electric motor powerlimit on DC side. Positive power means power flowing into inverter.
      frame BecmPropFr03: id 0x178, to IEM, frame-length=8, can-addressing-mode=STANDARD, can-fd-frame-support=false, can-frame-rx-behavior=CAN-20
        pdu BecmPropSignalIpdu03: length=8, unused-bit-pattern=0
          signal isHvBattSoc: start 47, 11 bit, big-endian, data-type-policy=NETWORK-REPRESENTATION-FROM-COM-SPEC, init-value=0, base-type=Perc7_2, compu {phys=raw*0.05 for raw 0..2000; unit %}, update-indication-bit-position=52, to IEM  # Actual state of charge of the Hv Battery.
      frame EcmPropFr02: id 0x66, to IEM, frame-length=8, can-addressing-mode=STANDARD, can-fd-frame-support=false, can-frame-rx-behavior=CAN-20
        pdu ECMPropSignalIPDU02: length=8, unused-bit-pattern=0
          signal isWhlMotSysModReq: start 58, 3 bit, big-endian, data-type-policy=NETWORK-REPRESENTATION-FROM-COM-SPEC, init-value=0, base-type=WhlMotSysModStsTyp1_2, compu-method=WhlMotSysModStsTyp1_1, update-indication-bit-position=59, to IEM  # Mode request for motor drive system connected to wheel shaft.
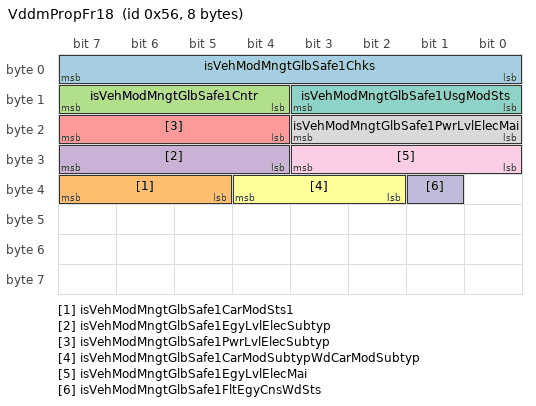
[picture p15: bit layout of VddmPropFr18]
      frame VddmPropFr18: id 0x56, to IEM, frame-length=8, can-addressing-mode=STANDARD, can-fd-frame-support=false, can-frame-rx-behavior=CAN-20
        pdu VDDMPropSignalIPDU18: length=8, unused-bit-pattern=0
          signal isVehModMngtGlbSafe1Chks: start 7, 8 bit, big-endian, data-type-policy=NETWORK-REPRESENTATION-FROM-COM-SPEC, init-value=0, base-type=UInt8_2, compu {identical; unit Unitless}, category=VALUE, to IEM  # Checksum
          signal isVehModMngtGlbSafe1CarModSts1: start 39, 3 bit, big-endian, data-type-policy=NETWORK-REPRESENTATION-FROM-COM-SPEC, init-value=0, base-type=CarModSts1_2, compu-method=CarModSts1_1, category=VALUE, to IEM  # CarMode Status
          signal isVehModMngtGlbSafe1Cntr: start 15, 4 bit, big-endian, data-type-policy=NETWORK-REPRESENTATION-FROM-COM-SPEC, init-value=0, base-type=UInt4_2, compu {identical; unit Unitless}, category=VALUE, to IEM  # Counter
          signal isVehModMngtGlbSafe1EgyLvlElecSubtyp: start 31, 4 bit, big-endian, data-type-policy=NETWORK-REPRESENTATION-FROM-COM-SPEC, init-value=0, base-type=UInt4_2, compu {identical; unit Unitless}, category=VALUE, to IEM  # Substate of the energy level in the vehicle.
          signal isVehModMngtGlbSafe1PwrLvlElecSubtyp: start 23, 4 bit, big-endian, data-type-policy=NETWORK-REPRESENTATION-FROM-COM-SPEC, init-value=0, base-type=UInt4_2, compu {identical; unit Unitless}, category=VALUE, to IEM  # Substate of the power level in the vehicle.
          signal isVehModMngtGlbSafe1CarModSubtypWdCarModSubtyp: start 36, 3 bit, big-endian, data-type-policy=NETWORK-REPRESENTATION-FROM-COM-SPEC, init-value=0, base-type=Nr5_2, compu {identical; unit Unitless}, category=VALUE, to IEM  # CarMode substate status
          signal isVehModMngtGlbSafe1UsgModSts: start 11, 4 bit, big-endian, data-type-policy=NETWORK-REPRESENTATION-FROM-COM-SPEC, init-value=1, base-type=UsgModSts1_2, compu-method=UsgModSts1_1, category=VALUE, to IEM  # UsageMode Status
          signal isVehModMngtGlbSafe1PwrLvlElecMai: start 19, 4 bit, big-endian, data-type-policy=NETWORK-REPRESENTATION-FROM-COM-SPEC, init-value=0, base-type=UInt4_2, compu {identical; unit Unitless}, category=VALUE, to IEM  # Main Power level in the vehicle.
          signal isVehModMngtGlbSafe1EgyLvlElecMai: start 27, 4 bit, big-endian, data-type-policy=NETWORK-REPRESENTATION-FROM-COM-SPEC, init-value=0, base-type=UInt4_2, compu {identical; unit Unitless}, category=VALUE, to IEM  # Main energy level in the vehicle.
          signal isVehModMngtGlbSafe1FltEgyCnsWdSts: start 33, 1 bit, big-endian, data-type-policy=NETWORK-REPRESENTATION-FROM-COM-SPEC, init-value=0, base-type=FltEgyCns1_2, compu {0=FltEgyCns1_NoFlt, 1=FltEgyCns1_Flt; unit Unitless}, category=VALUE, to IEM  # High quiescent current detected by CEM via BMS.
          mapping igVehModMngtGlbSafe1_mrx: i-signal-group=igVehModMngtGlbSafe1, packing-byte-order=big-endian, start-position=7, update-indication-bit-position=32
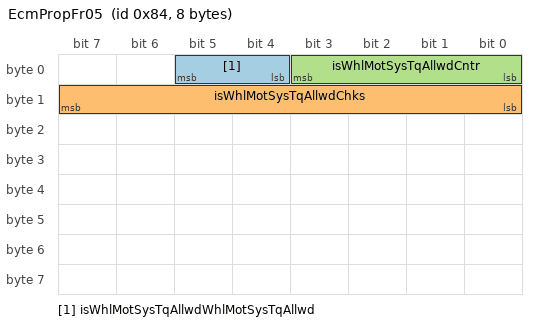
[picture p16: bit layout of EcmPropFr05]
      frame EcmPropFr05: id 0x84, to IEM, frame-length=8, can-addressing-mode=STANDARD, can-fd-frame-support=false, can-frame-rx-behavior=CAN-20
        pdu ECMPropSignalIPDU05: length=8, unused-bit-pattern=0
          signal isWhlMotSysTqAllwdWhlMotSysTqAllwd: start 5, 2 bit, big-endian, data-type-policy=NETWORK-REPRESENTATION-FROM-COM-SPEC, init-value=0, base-type=UInt2_2, compu {identical; unit Unitless}, category=VALUE, to IEM  # Indication if ERAD is allowed to apply propulsive or regenerative torque on wheels. Bit 0: Propulsive torque allowed Bit 1: Regenerative torque allowed
          signal isWhlMotSysTqAllwdChks: start 15, 8 bit, big-endian, data-type-policy=NETWORK-REPRESENTATION-FROM-COM-SPEC, init-value=0, base-type=UInt8_2, compu {identical; unit Unitless}, category=VALUE, to IEM  # Checksum for WhlMotSysTqAllwd
          signal isWhlMotSysTqAllwdCntr: start 3, 4 bit, big-endian, data-type-policy=NETWORK-REPRESENTATION-FROM-COM-SPEC, init-value=0, base-type=UInt4_2, compu {identical; unit Unitless}, category=VALUE, to IEM  # Counter for WhlMotSysTqAllwd
          mapping igWhlMotSysTqAllwd_mrx: i-signal-group=igWhlMotSysTqAllwd, packing-byte-order=big-endian, start-position=3, update-indication-bit-position=6
      frame VddmPropFr17: id 0x162, to IEM, frame-length=8, can-addressing-mode=STANDARD, can-fd-frame-support=false, can-frame-rx-behavior=CAN-20
        pdu VDDMPropSignalIPDU17: length=8, unused-bit-pattern=0
          signal isCarTiGlb: start 7, 32 bit, big-endian, data-type-policy=NETWORK-REPRESENTATION-FROM-COM-SPEC, init-value=0, base-type=CarTiGlb_2, compu {phys=raw*0.1 for raw 0..4294967295; unit s}, update-indication-bit-position=39, to IEM  # Presents a tiime value that shall be used by all ECUs to time-stamp diagnsotic trouble codes (DTC) according to the requirements for Global DTC snapshot data.
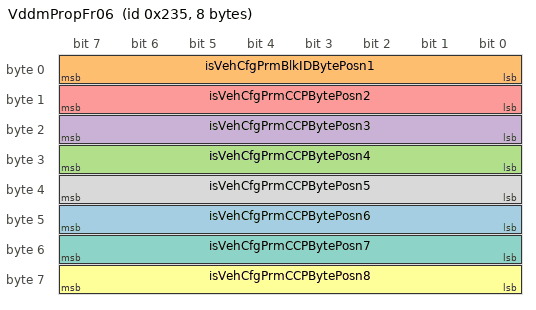
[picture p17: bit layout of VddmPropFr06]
      frame VddmPropFr06: id 0x235, to IEM, frame-length=8, can-addressing-mode=STANDARD, can-fd-frame-support=false, can-frame-rx-behavior=CAN-20
        pdu VDDMPropSignalIPDU06: length=8, unused-bit-pattern=0
          signal isVehCfgPrmCCPBytePosn6: start 47, 8 bit, big-endian, data-type-policy=NETWORK-REPRESENTATION-FROM-COM-SPEC, init-value=0, base-type=Nr2_3, compu {phys=raw for raw 0..255; unit Unitless}, category=VALUE, to IEM  # (BlockID-1)*7 + 5.
          signal isVehCfgPrmBlkIDBytePosn1: start 7, 8 bit, big-endian, data-type-policy=NETWORK-REPRESENTATION-FROM-COM-SPEC, init-value=0, base-type=Nr2_3, compu {phys=raw for raw 0..255; unit Unitless}, category=VALUE, to IEM  # signal block counter.
          signal isVehCfgPrmCCPBytePosn4: start 31, 8 bit, big-endian, data-type-policy=NETWORK-REPRESENTATION-FROM-COM-SPEC, init-value=0, base-type=Nr2_3, compu {phys=raw for raw 0..255; unit Unitless}, category=VALUE, to IEM  # (BlockID-1)*7 + 3.
          signal isVehCfgPrmCCPBytePosn3: start 23, 8 bit, big-endian, data-type-policy=NETWORK-REPRESENTATION-FROM-COM-SPEC, init-value=0, base-type=Nr2_3, compu {phys=raw for raw 0..255; unit Unitless}, category=VALUE, to IEM  # (BlockID-1)*7 + 2.
          signal isVehCfgPrmCCPBytePosn2: start 15, 8 bit, big-endian, data-type-policy=NETWORK-REPRESENTATION-FROM-COM-SPEC, init-value=0, base-type=Nr2_3, compu {phys=raw for raw 0..255; unit Unitless}, category=VALUE, to IEM  # (BlockID-1)*7 + 1.
          signal isVehCfgPrmCCPBytePosn8: start 63, 8 bit, big-endian, data-type-policy=NETWORK-REPRESENTATION-FROM-COM-SPEC, init-value=0, base-type=Nr2_3, compu {phys=raw for raw 0..255; unit Unitless}, category=VALUE, to IEM  # (BlockID-1)*7 + 7.
          signal isVehCfgPrmCCPBytePosn7: start 55, 8 bit, big-endian, data-type-policy=NETWORK-REPRESENTATION-FROM-COM-SPEC, init-value=0, base-type=Nr2_3, compu {phys=raw for raw 0..255; unit Unitless}, category=VALUE, to IEM  # (BlockID-1)*7 + 6.
          signal isVehCfgPrmCCPBytePosn5: start 39, 8 bit, big-endian, data-type-policy=NETWORK-REPRESENTATION-FROM-COM-SPEC, init-value=0, base-type=Nr2_3, compu {phys=raw for raw 0..255; unit Unitless}, category=VALUE, to IEM  # (BlockID-1)*7 + 4.
          mapping igVehCfgPrm_mrx: i-signal-group=igVehCfgPrm, packing-byte-order=big-endian, start-position=7
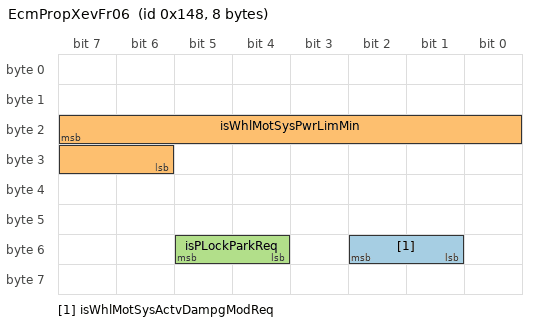
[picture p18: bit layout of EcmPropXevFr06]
      frame EcmPropXevFr06: id 0x148, to IEM, frame-length=8, can-addressing-mode=STANDARD, can-fd-frame-support=false, can-frame-rx-behavior=CAN-20
        pdu ECMPropSignalIPDU06: length=8, unused-bit-pattern=0
          signal isWhlMotSysActvDampgModReq: start 50, 2 bit, big-endian, data-type-policy=NETWORK-REPRESENTATION-FROM-COM-SPEC, init-value=0, base-type=WhlMotSysActvDampgModCodSts_2, compu-method=WhlMotSysActvDampgModCodSts_1, update-indication-bit-position=48, to IEM  # ERAD active damping mod request.
          signal isWhlMotSysPwrLimMin: start 23, 10 bit, big-endian, data-type-policy=NETWORK-REPRESENTATION-FROM-COM-SPEC, init-value=1022, base-type=PrpsnPwrLimMin_2, compu {phys=raw*0.5-511 for raw 0..1022; unit kW}, update-indication-bit-position=29, to IEM  # Minimum electric motor powerlimit on DC side. Positive power means power flowing into inverter.
          signal isPLockParkReq: start 53, 2 bit, big-endian, data-type-policy=NETWORK-REPRESENTATION-FROM-COM-SPEC, init-value=0, base-type=PLockParkRequest_1, compu-method=PLockParkRequest_1, update-indication-bit-position=51, to IEM  # Park request to P-Lock.
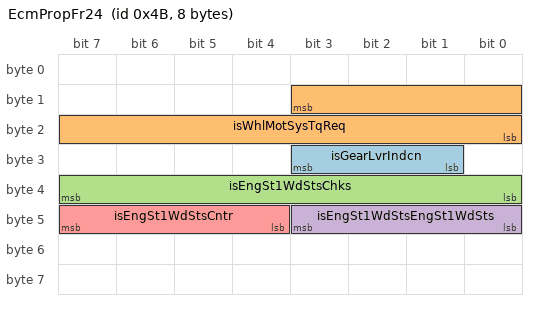
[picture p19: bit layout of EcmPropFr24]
      frame EcmPropFr24: id 0x4B, to IEM, frame-length=8, can-addressing-mode=STANDARD, can-fd-frame-support=false, can-frame-rx-behavior=CAN-20
        pdu EcmPropSignalIPdu24: length=8, unused-bit-pattern=0
          signal isGearLvrIndcn: start 27, 3 bit, big-endian, data-type-policy=NETWORK-REPRESENTATION-FROM-COM-SPEC, init-value=7, base-type=GearLvrIndcn2_2, compu-method=GearLvrIndcn2_1, update-indication-bit-position=24, to IEM  # Gear lever indication (drivetrain position) to the driver. If drivetrain position is not possible to decide signal is set to undefined. Valid for automatic vehicles.
          signal isWhlMotSysTqReq: start 11, 12 bit, big-endian, data-type-policy=NETWORK-REPRESENTATION-FROM-COM-SPEC, init-value=2047, base-type=HvTq1_2, compu {phys=raw*4-8188 for raw 0..4095; unit NewtonMeter}, update-indication-bit-position=12, to IEM  # Requested electric motor torque referred to the wheel axle. The torque is positive in the forward rotation direction.
          signal isEngSt1WdStsChks: start 39, 8 bit, big-endian, data-type-policy=NETWORK-REPRESENTATION-FROM-COM-SPEC, init-value=0, base-type=UInt8_2, compu {identical; unit Unitless}, category=VALUE, to IEM  # checksum
          signal isEngSt1WdStsEngSt1WdSts: start 43, 4 bit, big-endian, data-type-policy=NETWORK-REPRESENTATION-FROM-COM-SPEC, init-value=0, base-type=EngSt1_2, compu-method=EngSt1_1, category=VALUE, to IEM  # Signaling the state of the powerpack
          signal isEngSt1WdStsCntr: start 47, 4 bit, big-endian, data-type-policy=NETWORK-REPRESENTATION-FROM-COM-SPEC, init-value=0, base-type=UInt4_2, compu {identical; unit Unitless}, category=VALUE, to IEM  # counter
          mapping igEngSt1WdSts_mrx: i-signal-group=igEngSt1WdSts, packing-byte-order=big-endian, start-position=39, update-indication-bit-position=31
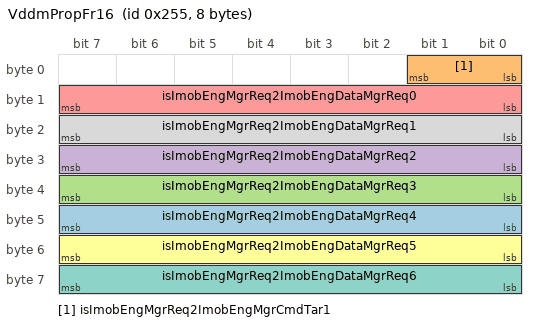
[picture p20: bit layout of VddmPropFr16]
      frame VddmPropFr16: id 0x255, to IEM, frame-length=8, can-addressing-mode=STANDARD, can-fd-frame-support=false, can-frame-rx-behavior=CAN-20
        pdu VDDMPropSignalIPDU16: length=8, unused-bit-pattern=0
          signal isImobEngMgrReq2ImobEngDataMgrReq4: start 47, 8 bit, big-endian, data-type-policy=NETWORK-REPRESENTATION-FROM-COM-SPEC, init-value=0, base-type=UInt8_2, compu {identical; unit Unitless}, category=VALUE, to IEM  # Command from CEM to IEM with desired immo status and 7 bytes of response Byte 4
          signal isImobEngMgrReq2ImobEngMgrCmdTar1: start 1, 2 bit, big-endian, data-type-policy=NETWORK-REPRESENTATION-FROM-COM-SPEC, init-value=0, base-type=ImobEngMgrReqCmd_2, compu-method=ImobEngMgrReqCmd_1, category=VALUE, to IEM  # Command from CEM to IEM with desired immo status and 7 bytes of response Command from CEM
          signal isImobEngMgrReq2ImobEngDataMgrReq3: start 39, 8 bit, big-endian, data-type-policy=NETWORK-REPRESENTATION-FROM-COM-SPEC, init-value=0, base-type=UInt8_2, compu {identical; unit Unitless}, category=VALUE, to IEM  # Command from CEM to IEM with desired immo status and 7 bytes of response Byte 3
          signal isImobEngMgrReq2ImobEngDataMgrReq2: start 31, 8 bit, big-endian, data-type-policy=NETWORK-REPRESENTATION-FROM-COM-SPEC, init-value=0, base-type=UInt8_2, compu {identical; unit Unitless}, category=VALUE, to IEM  # Command from CEM to IEM with desired immo status and 7 bytes of response Byte 2
          signal isImobEngMgrReq2ImobEngDataMgrReq0: start 15, 8 bit, big-endian, data-type-policy=NETWORK-REPRESENTATION-FROM-COM-SPEC, init-value=0, base-type=UInt8_2, compu {identical; unit Unitless}, category=VALUE, to IEM  # Command from CEM to IEM with desired immo status and 7 bytes of response Byte 0
          signal isImobEngMgrReq2ImobEngDataMgrReq5: start 55, 8 bit, big-endian, data-type-policy=NETWORK-REPRESENTATION-FROM-COM-SPEC, init-value=0, base-type=UInt8_2, compu {identical; unit Unitless}, category=VALUE, to IEM  # Command from CEM to IEM with desired immo status and 7 bytes of response Byte 5
          signal isImobEngMgrReq2ImobEngDataMgrReq6: start 63, 8 bit, big-endian, data-type-policy=NETWORK-REPRESENTATION-FROM-COM-SPEC, init-value=0, base-type=UInt8_2, compu {identical; unit Unitless}, category=VALUE, to IEM  # Command from CEM to IEM with desired immo status and 7 bytes of response Byte 6
          signal isImobEngMgrReq2ImobEngDataMgrReq1: start 23, 8 bit, big-endian, data-type-policy=NETWORK-REPRESENTATION-FROM-COM-SPEC, init-value=0, base-type=UInt8_2, compu {identical; unit Unitless}, category=VALUE, to IEM  # Command from CEM to IEM with desired immo status and 7 bytes of response Byte 1
          mapping igImobEngMgrReq2_mrx: i-signal-group=igImobEngMgrReq2, packing-byte-order=big-endian, start-position=1, update-indication-bit-position=2
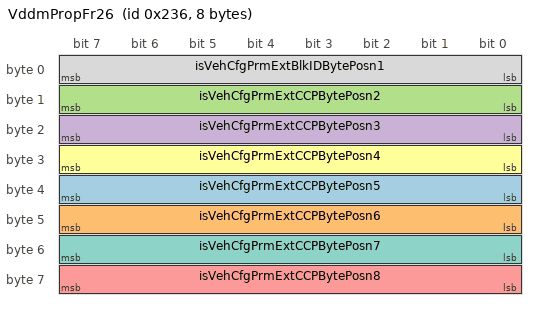
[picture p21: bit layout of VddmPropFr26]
      frame VddmPropFr26: id 0x236, to IEM, frame-length=8, can-addressing-mode=STANDARD, can-fd-frame-support=false, can-frame-rx-behavior=CAN-20
        pdu VddmPropSignalIPdu26: length=8, unused-bit-pattern=0
          signal isVehCfgPrmExtCCPBytePosn5: start 39, 8 bit, big-endian, data-type-policy=NETWORK-REPRESENTATION-FROM-COM-SPEC, init-value=0, base-type=Nr2_3, compu {phys=raw for raw 0..255; unit Unitless}, category=VALUE, to IEM  # CarConfigExtended BytePos5
          signal isVehCfgPrmExtCCPBytePosn6: start 47, 8 bit, big-endian, data-type-policy=NETWORK-REPRESENTATION-FROM-COM-SPEC, init-value=0, base-type=Nr2_3, compu {phys=raw for raw 0..255; unit Unitless}, category=VALUE, to IEM  # CarConfigExtended BytePos6
          signal isVehCfgPrmExtCCPBytePosn2: start 15, 8 bit, big-endian, data-type-policy=NETWORK-REPRESENTATION-FROM-COM-SPEC, init-value=0, base-type=Nr2_3, compu {phys=raw for raw 0..255; unit Unitless}, category=VALUE, to IEM  # CarConfigExtended BytePos2
          signal isVehCfgPrmExtCCPBytePosn3: start 23, 8 bit, big-endian, data-type-policy=NETWORK-REPRESENTATION-FROM-COM-SPEC, init-value=0, base-type=Nr2_3, compu {phys=raw for raw 0..255; unit Unitless}, category=VALUE, to IEM  # CarConfigExtended BytePos3
          signal isVehCfgPrmExtCCPBytePosn8: start 63, 8 bit, big-endian, data-type-policy=NETWORK-REPRESENTATION-FROM-COM-SPEC, init-value=0, base-type=Nr2_3, compu {phys=raw for raw 0..255; unit Unitless}, category=VALUE, to IEM  # CarConfigExtended BytePos8
          signal isVehCfgPrmExtCCPBytePosn4: start 31, 8 bit, big-endian, data-type-policy=NETWORK-REPRESENTATION-FROM-COM-SPEC, init-value=0, base-type=Nr2_3, compu {phys=raw for raw 0..255; unit Unitless}, category=VALUE, to IEM  # CarConfigExtended BytePos4
          signal isVehCfgPrmExtCCPBytePosn7: start 55, 8 bit, big-endian, data-type-policy=NETWORK-REPRESENTATION-FROM-COM-SPEC, init-value=0, base-type=Nr2_3, compu {phys=raw for raw 0..255; unit Unitless}, category=VALUE, to IEM  # CarConfigExtended BytePos7
          signal isVehCfgPrmExtBlkIDBytePosn1: start 7, 8 bit, big-endian, data-type-policy=NETWORK-REPRESENTATION-FROM-COM-SPEC, init-value=0, base-type=Nr2_3, compu {phys=raw for raw 0..255; unit Unitless}, category=VALUE, to IEM  # CarConfigExtended BlockID
          mapping igVehCfgPrmExt_mrx: i-signal-group=igVehCfgPrmExt, packing-byte-order=big-endian, start-position=7
      frame EcmPropFr08: id 0x171, to IEM, frame-length=8, can-addressing-mode=STANDARD, can-fd-frame-support=false, can-frame-rx-behavior=CAN-20
        pdu EcmPropSignalIPDU08: length=8, unused-bit-pattern=0
          signal isPrpsnFbLimnIndcn: start 22, 4 bit, big-endian, data-type-policy=NETWORK-REPRESENTATION-FROM-COM-SPEC, init-value=0, base-type=UInt4_2, compu {identical; unit Unitless}, update-indication-bit-position=23, to IEM  # Feedback signal that the present limitation has lead to a recofiguraton that has affected the driver.
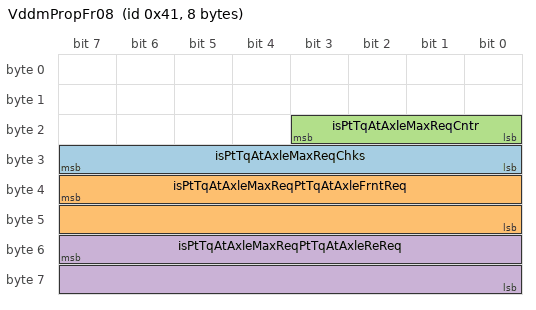
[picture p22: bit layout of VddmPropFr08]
      frame VddmPropFr08: id 0x41, to IEM, frame-length=8, can-addressing-mode=STANDARD, can-fd-frame-support=false, can-frame-rx-behavior=CAN-20
        pdu VDDMPropSignalIPDU08: length=8, unused-bit-pattern=0
          signal isPtTqAtAxleMaxReqChks: start 31, 8 bit, big-endian, data-type-policy=NETWORK-REPRESENTATION-FROM-COM-SPEC, init-value=0, base-type=UInt8_2, compu {identical; unit Unitless}, category=VALUE, to IEM  # checksum
          signal isPtTqAtAxleMaxReqPtTqAtAxleFrntReq: start 39, 16 bit, big-endian, data-type-policy=NETWORK-REPRESENTATION-FROM-COM-SPEC, init-value=20000, base-type=Tq2_2, compu {phys=raw for raw -20000..20000; unit NewtonMeter}, category=VALUE, to IEM  # Maximum allowed powertrain applied torque on the front axle.
          signal isPtTqAtAxleMaxReqCntr: start 19, 4 bit, big-endian, data-type-policy=NETWORK-REPRESENTATION-FROM-COM-SPEC, init-value=0, base-type=UInt4_2, compu {identical; unit Unitless}, category=VALUE, to IEM  # counter
          signal isPtTqAtAxleMaxReqPtTqAtAxleReReq: start 55, 16 bit, big-endian, data-type-policy=NETWORK-REPRESENTATION-FROM-COM-SPEC, init-value=20000, base-type=Tq2_2, compu {phys=raw for raw -20000..20000; unit NewtonMeter}, category=VALUE, to IEM  # Maximum allowed powertrain applied torque on the rear axle.
          mapping igPtTqAtAxleMaxReq_mrx: i-signal-group=igPtTqAtAxleMaxReq, packing-byte-order=big-endian, start-position=19, update-indication-bit-position=20
      frame EcmPropFr11: id 0x287, to IEM, frame-length=8, can-addressing-mode=STANDARD, can-fd-frame-support=false, can-frame-rx-behavior=CAN-20
        pdu EcmPropSignalIPDU11: length=8, unused-bit-pattern=0
          signal isCooltFlowForDtElec: start 41, 9 bit, big-endian, data-type-policy=NETWORK-REPRESENTATION-FROM-COM-SPEC, init-value=0, base-type=CooltFlow2_2, compu {phys=raw*0.1 for raw 0..511; unit L / min}, update-indication-bit-position=6, to IEM  # Predicted coolant low for Electric Drivetrain (ED) coolant circuit.
          signal isCooltTSigForDtElec: start 39, 11 bit, big-endian, data-type-policy=NETWORK-REPRESENTATION-FROM-COM-SPEC, init-value=400, base-type=CooltTHiResl_2, compu {phys=raw*0.1-40 for raw 0..1800; unit degC}, update-indication-bit-position=5, to IEM  # Coolant temperature measured by sensors installed in emotor cooling citcuit.
      frame VddmPropFr19: id 0x285, to IEM, frame-length=8, can-addressing-mode=STANDARD, can-fd-frame-support=false, can-frame-rx-behavior=CAN-20
        pdu VDDMPropSignalIPDU19: length=8, unused-bit-pattern=0
          signal isVehBattUSysU: start 15, 8 bit, big-endian, data-type-policy=NETWORK-REPRESENTATION-FROM-COM-SPEC, init-value=0, base-type=U1_2, compu {phys=raw*0.1 for raw 0..250; unit Volt}, category=VALUE, to IEM  # Vehicle System Voltage At 12V side
          signal isVehBattUSysUQf: start 1, 2 bit, big-endian, data-type-policy=NETWORK-REPRESENTATION-FROM-COM-SPEC, init-value=1, base-type=GenQf1_2, compu-method=GenQf1_1, category=VALUE, to IEM  # Present vehicle voltage measured by CEM with QF
          mapping igVehBattU_mrx: i-signal-group=igVehBattU, packing-byte-order=big-endian, start-position=1, update-indication-bit-position=2
          signal isBkpOfDstTrvld: start 20, 21 bit, big-endian, data-type-policy=NETWORK-REPRESENTATION-FROM-COM-SPEC, init-value=0, base-type=Len31_2, compu {phys=raw for raw 0..2000000; unit km}, update-indication-bit-position=21, to IEM  # total traveled distance.
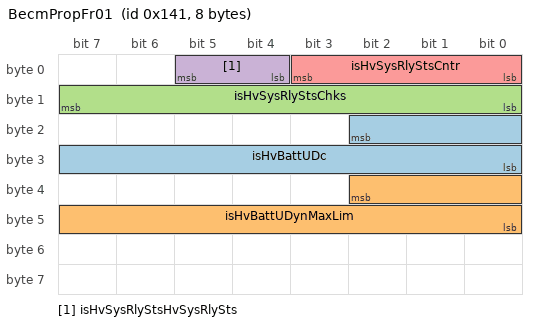
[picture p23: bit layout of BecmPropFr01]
      frame BecmPropFr01: id 0x141, to IEM, frame-length=8, can-addressing-mode=STANDARD, can-fd-frame-support=false, can-frame-rx-behavior=CAN-20
        pdu BecmPropSignalIpdu01: length=8, unused-bit-pattern=0
          signal isHvBattUDc: start 18, 11 bit, big-endian, data-type-policy=NETWORK-REPRESENTATION-FROM-COM-SPEC, init-value=0, base-type=HvU1_2, compu {phys=raw*0.25 for raw 0..2044; unit Volt}, update-indication-bit-position=19, to IEM  # Actual Hv Battery pack voltage (measuered before contactors, i.e. always giving pack voltage).
          signal isHvBattUDynMaxLim: start 34, 11 bit, big-endian, data-type-policy=NETWORK-REPRESENTATION-FROM-COM-SPEC, init-value=0, base-type=HvU1_2, compu {phys=raw*0.25 for raw 0..2044; unit Volt}, update-indication-bit-position=35, to IEM  # The pack voltage high limit of the Hv Battery, dynamically based on cell voltage distribution. At pack voltages above this limit, there is risk for contactor openeing due to too high cell voltage.
          signal isHvSysRlyStsChks: start 15, 8 bit, big-endian, data-type-policy=NETWORK-REPRESENTATION-FROM-COM-SPEC, init-value=0, base-type=UInt8_2, compu {identical; unit Unitless}, category=VALUE, to IEM  # Checksum for E2E
          signal isHvSysRlyStsHvSysRlySts: start 5, 2 bit, big-endian, data-type-policy=NETWORK-REPRESENTATION-FROM-COM-SPEC, init-value=2, base-type=HvActvnSts_2, compu-method=HvActvnSts_1, category=VALUE, to IEM  # Actual state of the main contactors.
          signal isHvSysRlyStsCntr: start 3, 4 bit, big-endian, data-type-policy=NETWORK-REPRESENTATION-FROM-COM-SPEC, init-value=0, base-type=UInt4_2, compu {identical; unit Unitless}, category=VALUE, to IEM  # Counter for E2E
          mapping igHvSysRlySts_mrx: i-signal-group=igHvSysRlySts, packing-byte-order=big-endian, start-position=3, update-indication-bit-position=22
      frame BecmPropFr02: id 0x175, to IEM, frame-length=8, can-addressing-mode=STANDARD, can-fd-frame-support=false, can-frame-rx-behavior=CAN-20
        pdu BecmPropSignalIpdu02: length=8, unused-bit-pattern=0
          signal isHvBattUDynMinLim: start 26, 11 bit, big-endian, data-type-policy=NETWORK-REPRESENTATION-FROM-COM-SPEC, init-value=0, base-type=HvU1_2, compu {phys=raw*0.25 for raw 0..2044; unit Volt}, update-indication-bit-position=27, to IEM  # The pack voltage low limit of the Hv Battery, dynamically based on cell voltage distribution. At pack voltages below this limit, there is risk for contactor openeing due to too low cell voltage
      frame VddmBcmPropdTCFr01: id 0x12E, to IEM, frame-length=8, can-addressing-mode=STANDARD, can-fd-frame-support=false, can-frame-rx-behavior=CAN-20
        pdu VddmBcmPropdTCSignalIPDU01: length=8, unused-bit-pattern=0
          signal isEscVariantToDmcChks: start 15, 8 bit, big-endian, data-type-policy=NETWORK-REPRESENTATION-FROM-COM-SPEC, init-value=0, base-type=UInt8_2, compu {identical; unit Unitless}, category=VALUE, to IEM  # Chks
          signal isEscVariantToDmcEscVariantToDmc: start 23, 8 bit, big-endian, data-type-policy=NETWORK-REPRESENTATION-FROM-COM-SPEC, init-value=0, base-type=UInt8_2, compu {identical; unit Unitless}, category=VALUE, to IEM  # Esc Variant
          signal isEscVariantToDmcCntr: start 3, 4 bit, big-endian, data-type-policy=NETWORK-REPRESENTATION-FROM-COM-SPEC, init-value=0, base-type=UInt4_2, compu {identical; unit Unitless}, category=VALUE, to IEM  # Cntr
          mapping igEscVariantToDmc_mrx: i-signal-group=igEscVariantToDmc, packing-byte-order=big-endian, start-position=3, update-indication-bit-position=4
      frame EcmPropFr28: id 0x191, to IEM, frame-length=8, can-addressing-mode=STANDARD, can-fd-frame-support=false, can-frame-rx-behavior=CAN-20
        pdu EcmPropSignalIPDU28: length=8, unused-bit-pattern=0
          signal isRearHeatModEnad: start 11, 2 bit, big-endian, data-type-policy=NETWORK-REPRESENTATION-FROM-COM-SPEC, init-value=2, base-type=FrntHeatModEnad_1, compu-method=FrntHeatModEnad_1, update-indication-bit-position=14, to IEM  # Active heating enabling signal for rear motor
          signal isRearHeatPwrAllwd: start 23, 8 bit, big-endian, data-type-policy=NETWORK-REPRESENTATION-FROM-COM-SPEC, init-value=0, base-type=IsgHeatPwr_1, compu {phys=raw*50 for raw 0..255; unit W}, update-indication-bit-position=15, to IEM  # The allowed electrial energy for active heating of the rear motor
      frame BecmPropFr15: id 0x143, to IEM, frame-length=8, can-addressing-mode=STANDARD, can-fd-frame-support=false, can-frame-rx-behavior=CAN-20
        pdu BecmPropSignalIpdu15: length=8, unused-bit-pattern=0
          signal isDCChrgnHndlSts: start 23, 3 bit, big-endian, data-type-policy=NETWORK-REPRESENTATION-FROM-COM-SPEC, init-value=0, base-type=OnBdChrgrHndlSts_2, compu-method=OnBdChrgrHndlSts_1, update-indication-bit-position=35, to IEM  # Fast charging gun connect state
      frame CddObcPropFr01: id 0x218, to IEM, frame-length=8, can-addressing-mode=STANDARD, can-fd-frame-support=false, can-frame-rx-behavior=CAN-20
        pdu CddObcPropSignalIPdu01: length=8, unused-bit-pattern=0
          signal isOnBdChrgrHndlSts1: start 19, 4 bit, big-endian, data-type-policy=NETWORK-REPRESENTATION-FROM-COM-SPEC, init-value=8, base-type=OnBdChrgrHndlSts1_2, compu-method=OnBdChrgrHndlSts1_2, update-indication-bit-position=20, to IEM  # Status of the Onboard Charger connection to the grid.
      pdu triggering PduTrIemToEtcUudtDcmIpdu{1..3}: pdu=IemToEtcUudtDcmIpdu{1..3}, from IEM
      pdu triggering PduTrVgmToIemDiagDcmIpdu: pdu=VgmToIemDiagDcmIpdu, to IEM
      pdu triggering PduTrIemToVgmDiagDcmIpdu: pdu=IemToVgmDiagDcmIpdu, from IEM
      pdu triggering PduTrVgmToAllFuncDiagDcmIpdu: pdu=VgmToAllFuncDiagDcmIpdu, to IEM
      pdu triggering PduTrEtcToAllJ1979OBDDiagDcmIpdu11: pdu=EtcToAllJ1979OBDDiagDcmIpdu11, to IEM
      pdu triggering PduTrEtcToIemJ1979OBDDiagDcmIpdu11: pdu=EtcToIemJ1979OBDDiagDcmIpdu11, to IEM
      pdu triggering PduTrIemToEtcJ1979OBDDiagDcmIpdu11: pdu=IemToEtcJ1979OBDDiagDcmIpdu11, from IEM
package /ECUExtractIEM/VehicleProject
  system SDB12010901: category=ECU_EXTRACT, ecu-extract-version=0.0.0;22/08/23, ECU.Cfg.Ver:1, pnc-vector-length=6, pnc-vector-offset=2, system-version=0.0.0;22/08/23, System.Ver: 0
    system mapping System_MAPPING
      data-mappings:
        sender-receiver-to-signal-group-mapping={data-element=IEM.TopLevelComposition.DmcStsRearToEsc.DmcStsRearToEsc, signal-group=DmcStsRearToEsc, type-mapping=sender-rec-record-type-mapping=record-element-mappings=[{application-record-element=DmcSts, system-signal=DmcStsRearToEscDmcSts}, {application-record-element=DmcStsToEsc_1/Chks, system-signal=DmcStsRearToEscChks}, {application-record-element=DmcStsToEsc_1/Cntr, system-signal=DmcStsRearToEscCntr}, {application-record-element=DmcActAppTarTq, system-signal=DmcStsRearToEscDmcActAppTarTq}, {application-record-element=DmcSWInfo, system-signal=DmcStsRearToEscDmcSWInfo}]}
        sender-receiver-to-signal-group-mapping={data-element=IEM.TopLevelComposition.IemGeneric.IemGeneric, signal-group=IemGeneric, type-mapping=sender-rec-record-type-mapping=record-element-mappings=[{application-record-element=FltAlrmSt, system-signal=IemGenericFltAlrmSt}, {application-record-element=ModStatusRms, system-signal=IemGenericModStatusRms}, {application-record-element=IacAlrmSt, system-signal=IemGenericIacAlrmSt}, {application-record-element=EMSeqNr, system-signal=IemGenericEMSeqNr}, {application-record-element=SpdAlrmSt, system-signal=IemGenericSpdAlrmSt}, {application-record-element=MotTAlrmSt, system-signal=IemGenericMotTAlrmSt}, {application-record-element=UDcAlrmSt, system-signal=IemGenericUDcAlrmSt}, {application-record-element=EMQnty, system-signal=IemGenericEMQnty}, {application-record-element=InvrtTAlrmSt, system-signal=IemGenericInvrtTAlrmSt}, {application-record-element=ADAlrmSt, system-signal=IemGenericADAlrmSt}, {application-record-element=DTCHig, system-signal=IemGenericDTCHig}, {application-record-element=DTCLow, system-signal=IemGenericDTCLow}, {application-record-element=RslAlrmSt, system-signal=IemGenericRslAlrmSt}, {application-record-element=DTCMid, system-signal=IemGenericDTCMid}, {application-record-element=DTCSts, system-signal=IemGenericDTCSts}, {application-record-element=TypeInfo, system-signal=IemGenericTypeInfo}]}
        sender-receiver-to-signal-group-mapping={data-element=IEM.TopLevelComposition.IEMTestFr1.IEMTestFr1, signal-group=IEMTestFr1, type-mapping=sender-rec-record-type-mapping=record-element-mappings=[{application-record-element=Byte7, system-signal=IEMTestFr1Byte7}, {application-record-element=Byte2, system-signal=IEMTestFr1Byte2}, {application-record-element=Byte6, system-signal=IEMTestFr1Byte6}, {application-record-element=Byte4, system-signal=IEMTestFr1Byte4}, {application-record-element=Byte3, system-signal=IEMTestFr1Byte3}, {application-record-element=Byte1, system-signal=IEMTestFr1Byte1}, {application-record-element=Byte0, system-signal=IEMTestFr1Byte0}, {application-record-element=Byte5, system-signal=IEMTestFr1Byte5}]}
        sender-receiver-to-signal-group-mapping={data-element=IEM.TopLevelComposition.IEMTestFr2.IEMTestFr2, signal-group=IEMTestFr2, type-mapping=sender-rec-record-type-mapping=record-element-mappings=[{application-record-element=Byte2, system-signal=IEMTestFr2Byte2}, {application-record-element=Byte3, system-signal=IEMTestFr2Byte3}, {application-record-element=Byte5, system-signal=IEMTestFr2Byte5}, {application-record-element=Byte7, system-signal=IEMTestFr2Byte7}, {application-record-element=Byte6, system-signal=IEMTestFr2Byte6}, {application-record-element=Byte4, system-signal=IEMTestFr2Byte4}, {application-record-element=Byte1, system-signal=IEMTestFr2Byte1}, {application-record-element=Byte0, system-signal=IEMTestFr2Byte0}]}
        sender-receiver-to-signal-group-mapping={data-element=IEM.TopLevelComposition.IEMTestFr3.IEMTestFr3, signal-group=IEMTestFr3, type-mapping=sender-rec-record-type-mapping=record-element-mappings=[{application-record-element=Byte0, system-signal=IEMTestFr3Byte0}, {application-record-element=Byte4, system-signal=IEMTestFr3Byte4}, {application-record-element=Byte5, system-signal=IEMTestFr3Byte5}, {application-record-element=Byte6, system-signal=IEMTestFr3Byte6}, {application-record-element=Byte1, system-signal=IEMTestFr3Byte1}, {application-record-element=Byte7, system-signal=IEMTestFr3Byte7}, {application-record-element=Byte2, system-signal=IEMTestFr3Byte2}, {application-record-element=Byte3, system-signal=IEMTestFr3Byte3}]}
        sender-receiver-to-signal-group-mapping={data-element=IEM.TopLevelComposition.ImobEngChk2.ImobEngChk2, signal-group=ImobEngChk2, type-mapping=sender-rec-record-type-mapping=record-element-mappings=[{application-record-element=ImobEngDataChk2, system-signal=ImobEngChk2ImobEngDataChk2}, {application-record-element=ImobEngDataChk3, system-signal=ImobEngChk2ImobEngDataChk3}, {application-record-element=ImobEngDataChk4, system-signal=ImobEngChk2ImobEngDataChk4}, {application-record-element=ImobEngDataChk6, system-signal=ImobEngChk2ImobEngDataChk6}, {application-record-element=ImobEngChkSts, system-signal=ImobEngChk2ImobEngChkSts}, {application-record-element=ImobEngDataChk0, system-signal=ImobEngChk2ImobEngDataChk0}, {application-record-element=ImobEngDataChk5, system-signal=ImobEngChk2ImobEngDataChk5}, {application-record-element=ImobEngDataChk1, system-signal=ImobEngChk2ImobEngDataChk1}]}
        sender-receiver-to-signal-mapping={data-element=IEM.TopLevelComposition.ImobEngSts2.ImobEngSts2, system-signal=ImobEngSts2}
        sender-receiver-to-signal-mapping={data-element=IEM.TopLevelComposition.PLockFltIndcRe.PLockFltIndcRe, system-signal=PLockFltIndcRe}
        sender-receiver-to-signal-mapping={data-element=IEM.TopLevelComposition.PLockFltLvlRe.PLockFltLvlRe, system-signal=PLockFltLvlRe}
        sender-receiver-to-signal-mapping={data-element=IEM.TopLevelComposition.PLockParkStsRe.PLockParkStsRe, system-signal=PLockParkStsRe}
        sender-receiver-to-signal-mapping={data-element=IEM.TopLevelComposition.WhlMotClrRdyReq.WhlMotClrRdyReq, system-signal=WhlMotClrRdyReq}
        sender-receiver-to-signal-mapping={data-element=IEM.TopLevelComposition.WhlMotCooltFlowMinReq.WhlMotCooltFlowMinReq, system-signal=WhlMotCooltFlowMinReq}
        sender-receiver-to-signal-mapping={data-element=IEM.TopLevelComposition.WhlMotSysCoolgReq.WhlMotSysCoolgReq, system-signal=WhlMotSysCoolgReq}
        sender-receiver-to-signal-mapping={data-element=IEM.TopLevelComposition.WhlMotSysCooltT.WhlMotSysCooltT, system-signal=WhlMotSysCooltT}
        sender-receiver-to-signal-mapping={data-element=IEM.TopLevelComposition.WhlMotSysErrIndcnReq.WhlMotSysErrIndcnReq, system-signal=WhlMotSysErrIndcnReq}
        sender-receiver-to-signal-mapping={data-element=IEM.TopLevelComposition.WhlMotSysHeatFdBck.WhlMotSysHeatFdBck, system-signal=WhlMotSysHeatFdBck}
        sender-receiver-to-signal-mapping={data-element=IEM.TopLevelComposition.WhlMotSysHeatPwrAct.WhlMotSysHeatPwrAct, system-signal=WhlMotSysHeatPwrAct}
        sender-receiver-to-signal-mapping={data-element=IEM.TopLevelComposition.WhlMotSysHeatPwrMax.WhlMotSysHeatPwrMax, system-signal=WhlMotSysHeatPwrMax}
        sender-receiver-to-signal-mapping={data-element=IEM.TopLevelComposition.WhlMotSysIdc.WhlMotSysIdc, system-signal=WhlMotSysIdc}
        sender-receiver-to-signal-mapping={data-element=IEM.TopLevelComposition.WhlMotSysInvrT.WhlMotSysInvrT, system-signal=WhlMotSysInvrT}
        sender-receiver-to-signal-mapping={data-element=IEM.TopLevelComposition.WhlMotSysLimnIndcn.WhlMotSysLimnIndcn, system-signal=WhlMotSysLimnIndcn}
        sender-receiver-to-signal-mapping={data-element=IEM.TopLevelComposition.WhlMotSysModSts.WhlMotSysModSts, system-signal=WhlMotSysModSts}
        sender-receiver-to-signal-mapping={data-element=IEM.TopLevelComposition.WhlMotSysMotT.WhlMotSysMotT, system-signal=WhlMotSysMotT}
        sender-receiver-to-signal-mapping={data-element=IEM.TopLevelComposition.WhlMotSysSpdAct.WhlMotSysSpdAct, system-signal=WhlMotSysSpdAct}
        sender-receiver-to-signal-group-mapping={data-element=IEM.TopLevelComposition.WhlMotSysSpdActSafe.WhlMotSysSpdActSafe, signal-group=WhlMotSysSpdActSafe, type-mapping=sender-rec-record-type-mapping=record-element-mappings=[{application-record-element=SpdSgnSafe_1/Chks, system-signal=WhlMotSysSpdActSafeChks}, {application-record-element=IsgSpdWSgnTyp, system-signal=WhlMotSysSpdActSafeIsgSpdWSgnTyp}, {application-record-element=Qf, system-signal=WhlMotSysSpdActSafeQf}, {application-record-element=SpdSgnSafe_1/Cntr, system-signal=WhlMotSysSpdActSafeCntr}]}
        sender-receiver-to-signal-group-mapping={data-element=IEM.TopLevelComposition.WhlMotSysTqAvl.WhlMotSysTqAvl, signal-group=WhlMotSysTqAvl, type-mapping=sender-rec-record-type-mapping=record-element-mappings=[{application-record-element=TqAvlMin, system-signal=WhlMotSysTqAvlTqAvlMin}, {application-record-element=TqAvlMax, system-signal=WhlMotSysTqAvlTqAvlMax}]}
        sender-receiver-to-signal-group-mapping={data-element=IEM.TopLevelComposition.WhlMotSysTqEst.WhlMotSysTqEst, signal-group=WhlMotSysTqEst, type-mapping=sender-rec-record-type-mapping=record-element-mappings=[{application-record-element=IsgTqActSafe2_4/Cntr, system-signal=WhlMotSysTqEstCntr}, {application-record-element=IsgTqAct, system-signal=WhlMotSysTqEstIsgTqAct}, {application-record-element=QualityFactor, system-signal=WhlMotSysTqEstQualityFactor}, {application-record-element=IsgTqActSafe2_4/Chks, system-signal=WhlMotSysTqEstChks}]}
        sender-receiver-to-signal-mapping={data-element=IEM.TopLevelComposition.WhlMotSysUdc.WhlMotSysUdc, system-signal=WhlMotSysUdc}
        sender-receiver-to-signal-mapping={data-element=IEM.TopLevelComposition.BkpOfDstTrvld.BkpOfDstTrvld, system-signal=BkpOfDstTrvld}
        sender-receiver-to-signal-mapping={data-element=IEM.TopLevelComposition.CarTiGlb.CarTiGlb, system-signal=CarTiGlb}
        sender-receiver-to-signal-mapping={data-element=IEM.TopLevelComposition.CooltFlowForDtElec.CooltFlowForDtElec, system-signal=CooltFlowForDtElec}
        sender-receiver-to-signal-mapping={data-element=IEM.TopLevelComposition.CooltTSigForDtElec.CooltTSigForDtElec, system-signal=CooltTSigForDtElec}
        sender-receiver-to-signal-group-mapping={data-element=IEM.TopLevelComposition.CrashStsSafe.CrashStsSafe, signal-group=CrashStsSafe, type-mapping=sender-rec-record-type-mapping=record-element-mappings=[{application-record-element=CrashStsSafe_1/Cntr, system-signal=CrashStsSafeCntr}, {application-record-element=Sts, system-signal=CrashStsSafeSts}, {application-record-element=CrashStsSafe_1/Chks, system-signal=CrashStsSafeChks}]}
        sender-receiver-to-signal-mapping={data-element=IEM.TopLevelComposition.DCChrgnHndlSts.DCChrgnHndlSts, system-signal=DCChrgnHndlSts}
        sender-receiver-to-signal-mapping={data-element=IEM.TopLevelComposition.DrvgCyc.DrvgCyc, system-signal=DrvgCyc}
        sender-receiver-to-signal-group-mapping={data-element=IEM.TopLevelComposition.EngSt1WdSts.EngSt1WdSts, signal-group=EngSt1WdSts, type-mapping=sender-rec-record-type-mapping=record-element-mappings=[{application-record-element=EngSt1WdSts_1/Chks, system-signal=EngSt1WdStsChks}, {application-record-element=EngSt1WdSts, system-signal=EngSt1WdStsEngSt1WdSts}, {application-record-element=EngSt1WdSts_1/Cntr, system-signal=EngSt1WdStsCntr}]}
        sender-receiver-to-signal-group-mapping={data-element=IEM.TopLevelComposition.EscVariantToDmc.EscVariantToDmc, signal-group=EscVariantToDmc, type-mapping=sender-rec-record-type-mapping=record-element-mappings=[{application-record-element=EscVariantToDmc_1/Chks, system-signal=EscVariantToDmcChks}, {application-record-element=EscVariantToDmc, system-signal=EscVariantToDmcEscVariantToDmc}, {application-record-element=EscVariantToDmc_1/Cntr, system-signal=EscVariantToDmcCntr}]}
        sender-receiver-to-signal-mapping={data-element=IEM.TopLevelComposition.GearLvrIndcn.GearLvrIndcn, system-signal=GearLvrIndcn}
        sender-receiver-to-signal-mapping={data-element=IEM.TopLevelComposition.HvBattSoc.HvBattSoc, system-signal=HvBattSoc}
        sender-receiver-to-signal-mapping={data-element=IEM.TopLevelComposition.HvBattUDc.HvBattUDc, system-signal=HvBattUDc}
        sender-receiver-to-signal-mapping={data-element=IEM.TopLevelComposition.HvBattUDynMaxLim.HvBattUDynMaxLim, system-signal=HvBattUDynMaxLim}
        sender-receiver-to-signal-mapping={data-element=IEM.TopLevelComposition.HvBattUDynMinLim.HvBattUDynMinLim, system-signal=HvBattUDynMinLim}
        sender-receiver-to-signal-group-mapping={data-element=IEM.TopLevelComposition.HvSysRlySts.HvSysRlySts, signal-group=HvSysRlySts, type-mapping=sender-rec-record-type-mapping=record-element-mappings=[{application-record-element=HvSysRlySts_1/Chks, system-signal=HvSysRlyStsChks}, {application-record-element=HvSysRlySts, system-signal=HvSysRlyStsHvSysRlySts}, {application-record-element=HvSysRlySts_1/Cntr, system-signal=HvSysRlyStsCntr}]}
        sender-receiver-to-signal-group-mapping={data-element=IEM.TopLevelComposition.ImobEngMgrReq2.ImobEngMgrReq2, signal-group=ImobEngMgrReq2, type-mapping=sender-rec-record-type-mapping=record-element-mappings=[{application-record-element=ImobEngDataMgrReq4, system-signal=ImobEngMgrReq2ImobEngDataMgrReq4}, {application-record-element=ImobEngMgrCmdTar1, system-signal=ImobEngMgrReq2ImobEngMgrCmdTar1}, {application-record-element=ImobEngDataMgrReq3, system-signal=ImobEngMgrReq2ImobEngDataMgrReq3}, {application-record-element=ImobEngDataMgrReq2, system-signal=ImobEngMgrReq2ImobEngDataMgrReq2}, {application-record-element=ImobEngDataMgrReq0, system-signal=ImobEngMgrReq2ImobEngDataMgrReq0}, {application-record-element=ImobEngDataMgrReq5, system-signal=ImobEngMgrReq2ImobEngDataMgrReq5}, {application-record-element=ImobEngDataMgrReq6, system-signal=ImobEngMgrReq2ImobEngDataMgrReq6}, {application-record-element=ImobEngDataMgrReq1, system-signal=ImobEngMgrReq2ImobEngDataMgrReq1}]}
        sender-receiver-to-signal-mapping={data-element=IEM.TopLevelComposition.OnBdChrgrHndlSts1.OnBdChrgrHndlSts1, system-signal=OnBdChrgrHndlSts1}
        sender-receiver-to-signal-mapping={data-element=IEM.TopLevelComposition.PLockParkReq.PLockParkReq, system-signal=PLockParkReq}
        sender-receiver-to-signal-mapping={data-element=IEM.TopLevelComposition.PrpsnFbLimnIndcn.PrpsnFbLimnIndcn, system-signal=PrpsnFbLimnIndcn}
        sender-receiver-to-signal-group-mapping={data-element=IEM.TopLevelComposition.PtTqAtAxleMaxReq.PtTqAtAxleMaxReq, signal-group=PtTqAtAxleMaxReq, type-mapping=sender-rec-record-type-mapping=record-element-mappings=[{application-record-element=PtTqAtAxleReq_1/Chks, system-signal=PtTqAtAxleMaxReqChks}, {application-record-element=PtTqAtAxleFrntReq, system-signal=PtTqAtAxleMaxReqPtTqAtAxleFrntReq}, {application-record-element=PtTqAtAxleReq_1/Cntr, system-signal=PtTqAtAxleMaxReqCntr}, {application-record-element=PtTqAtAxleReReq, system-signal=PtTqAtAxleMaxReqPtTqAtAxleReReq}]}
        sender-receiver-to-signal-mapping={data-element=IEM.TopLevelComposition.RearHeatModEnad.RearHeatModEnad, system-signal=RearHeatModEnad}
        sender-receiver-to-signal-mapping={data-element=IEM.TopLevelComposition.RearHeatPwrAllwd.RearHeatPwrAllwd, system-signal=RearHeatPwrAllwd}
        sender-receiver-to-signal-mapping={data-element=IEM.TopLevelComposition.SpdRotlForWhlsAtAxleRe.SpdRotlForWhlsAtAxleRe, system-signal=SpdRotlForWhlsAtAxleRe}
        sender-receiver-to-signal-group-mapping={data-element=IEM.TopLevelComposition.StcStsToDmc.StcStsToDmc, signal-group=StcStsToDmc, type-mapping=sender-rec-record-type-mapping=record-element-mappings=[{application-record-element=EngRotTarSpdDMCFrnt, system-signal=StcStsToDmcEngRotTarSpdDMCFrnt}, {application-record-element=StcStsToDmcFrnt, system-signal=StcStsToDmcFrnt}, {application-record-element=EngRotTarSpdDMCRear, system-signal=StcStsToDmcEngRotTarSpdDMCRear}, {application-record-element=StcStsToDmc_1/Chks, system-signal=StcStsToDmcChks}, {application-record-element=StcStsToDmc_1/Cntr, system-signal=StcStsToDmcCntr}, {application-record-element=StcStsToDmcRear, system-signal=StcStsToDmcRear}]}
        sender-receiver-to-signal-group-mapping={data-element=IEM.TopLevelComposition.VehBattU.VehBattU, signal-group=VehBattU, type-mapping=sender-rec-record-type-mapping=record-element-mappings=[{application-record-element=SysU, system-signal=VehBattUSysU}, {application-record-element=SysUQf, system-signal=VehBattUSysUQf}]}
        sender-receiver-to-signal-group-mapping={data-element=IEM.TopLevelComposition.VehCfgPrm.VehCfgPrm, signal-group=VehCfgPrm, type-mapping=sender-rec-record-type-mapping=record-element-mappings=[{application-record-element=CCPBytePosn6, system-signal=VehCfgPrmCCPBytePosn6}, {application-record-element=BlkIDBytePosn1, system-signal=VehCfgPrmBlkIDBytePosn1}, {application-record-element=CCPBytePosn4, system-signal=VehCfgPrmCCPBytePosn4}, {application-record-element=CCPBytePosn3, system-signal=VehCfgPrmCCPBytePosn3}, {application-record-element=CCPBytePosn2, system-signal=VehCfgPrmCCPBytePosn2}, {application-record-element=CCPBytePosn8, system-signal=VehCfgPrmCCPBytePosn8}, {application-record-element=CCPBytePosn7, system-signal=VehCfgPrmCCPBytePosn7}, {application-record-element=CCPBytePosn5, system-signal=VehCfgPrmCCPBytePosn5}]}
        sender-receiver-to-signal-group-mapping={data-element=IEM.TopLevelComposition.VehCfgPrmExt.VehCfgPrmExt, signal-group=VehCfgPrmExt, type-mapping=sender-rec-record-type-mapping=record-element-mappings=[{application-record-element=CCPBytePosn5, system-signal=VehCfgPrmExtCCPBytePosn5}, {application-record-element=CCPBytePosn6, system-signal=VehCfgPrmExtCCPBytePosn6}, {application-record-element=CCPBytePosn2, system-signal=VehCfgPrmExtCCPBytePosn2}, {application-record-element=CCPBytePosn3, system-signal=VehCfgPrmExtCCPBytePosn3}, {application-record-element=CCPBytePosn8, system-signal=VehCfgPrmExtCCPBytePosn8}, {application-record-element=CCPBytePosn4, system-signal=VehCfgPrmExtCCPBytePosn4}, {application-record-element=CCPBytePosn7, system-signal=VehCfgPrmExtCCPBytePosn7}, {application-record-element=BlkIDBytePosn1, system-signal=VehCfgPrmExtBlkIDBytePosn1}]}
        sender-receiver-to-signal-group-mapping={data-element=IEM.TopLevelComposition.VehModMngtGlbSafe1.VehModMngtGlbSafe1, signal-group=VehModMngtGlbSafe1, type-mapping=sender-rec-record-type-mapping=record-element-mappings=[{application-record-element=VehModMngtGlbSafe1_2/Chks, system-signal=VehModMngtGlbSafe1Chks}, {application-record-element=CarModSts1, system-signal=VehModMngtGlbSafe1CarModSts1}, {application-record-element=VehModMngtGlbSafe1_2/Cntr, system-signal=VehModMngtGlbSafe1Cntr}, {application-record-element=EgyLvlElecSubtyp, system-signal=VehModMngtGlbSafe1EgyLvlElecSubtyp}, {application-record-element=PwrLvlElecSubtyp, system-signal=VehModMngtGlbSafe1PwrLvlElecSubtyp}, {application-record-element=CarModSubtypWdCarModSubtyp, system-signal=VehModMngtGlbSafe1CarModSubtypWdCarModSubtyp}, {application-record-element=UsgModSts, system-signal=VehModMngtGlbSafe1UsgModSts}, {application-record-element=PwrLvlElecMai, system-signal=VehModMngtGlbSafe1PwrLvlElecMai}, {application-record-element=EgyLvlElecMai, system-signal=VehModMngtGlbSafe1EgyLvlElecMai}, {application-record-element=FltEgyCnsWdSts, system-signal=VehModMngtGlbSafe1FltEgyCnsWdSts}]}
        sender-receiver-to-signal-group-mapping={data-element=IEM.TopLevelComposition.VehMtnSt.VehMtnSt, signal-group=VehMtnSt, type-mapping=sender-rec-record-type-mapping=record-element-mappings=[{application-record-element=VehMtnStChks, system-signal=VehMtnStChks}, {application-record-element=VehMtnStCntr, system-signal=VehMtnStCntr}, {application-record-element=VehMtnSt, system-signal=VehMtnStVehMtnSt}]}
        sender-receiver-to-signal-group-mapping={data-element=IEM.TopLevelComposition.VehSpdLgt.VehSpdLgt, signal-group=VehSpdLgt, type-mapping=sender-rec-record-type-mapping=record-element-mappings=[{application-record-element=VehSpdLgtQf, system-signal=VehSpdLgtQf}, {application-record-element=VehSpdLgtCntr, system-signal=VehSpdLgtCntr}, {application-record-element=VehSpdLgtChks, system-signal=VehSpdLgtChks}, {application-record-element=VehSpdLgtA, system-signal=VehSpdLgtA}]}
        sender-receiver-to-signal-mapping={data-element=IEM.TopLevelComposition.WhlMotSysActvDampgModReq.WhlMotSysActvDampgModReq, system-signal=WhlMotSysActvDampgModReq}
        sender-receiver-to-signal-mapping={data-element=IEM.TopLevelComposition.WhlMotSysModReq.WhlMotSysModReq, system-signal=WhlMotSysModReq}
        sender-receiver-to-signal-mapping={data-element=IEM.TopLevelComposition.WhlMotSysPwrLimMax.WhlMotSysPwrLimMax, system-signal=WhlMotSysPwrLimMax}
        sender-receiver-to-signal-mapping={data-element=IEM.TopLevelComposition.WhlMotSysPwrLimMin.WhlMotSysPwrLimMin, system-signal=WhlMotSysPwrLimMin}
        sender-receiver-to-signal-group-mapping={data-element=IEM.TopLevelComposition.WhlMotSysTqAllwd.WhlMotSysTqAllwd, signal-group=WhlMotSysTqAllwd, type-mapping=sender-rec-record-type-mapping=record-element-mappings=[{application-record-element=WhlMotSysTqAllwd, system-signal=WhlMotSysTqAllwdWhlMotSysTqAllwd}, {application-record-element=WhlMotSysTqAllwd_3/Chks, system-signal=WhlMotSysTqAllwdChks}, {application-record-element=WhlMotSysTqAllwd_3/Cntr, system-signal=WhlMotSysTqAllwdCntr}]}
        sender-receiver-to-signal-mapping={data-element=IEM.TopLevelComposition.WhlMotSysTqReq.WhlMotSysTqReq, system-signal=WhlMotSysTqReq}
      pnc-mappings:
        pnc-group=TxSPG_PropulsionCAN_PNC16, pnc-identifier=16, short-label=PNC16, vfc=TopLevelComposition.InfotainmentPush
        pnc-group=[TxSPG_PropulsionCAN_PNC24, RxSPG_PropulsionCAN_PNC24], pnc-identifier=24, short-label=PNC24, vfc=TopLevelComposition.PropulsionStart
        pnc-group=[TxSPG_PropulsionCAN_PNC25, RxSPG_PropulsionCAN_PNC25], pnc-identifier=25, short-label=PNC25, vfc=TopLevelComposition.ChargingHV
        pnc-group=[TxSPG_PropulsionCAN_PNC26, RxSPG_PropulsionCAN_PNC26], pnc-identifier=26, short-label=PNC26, vfc=[TopLevelComposition.ParkingDrivingClimatization, TopLevelComposition.Immobilizer]
        pnc-group=[TxSPG_PropulsionCAN_PNC27, RxSPG_PropulsionCAN_PNC27], pnc-identifier=27, short-label=PNC27, vfc=TopLevelComposition.TelematicsConnectivity
        pnc-group=[TxSPG_PropulsionCAN_PNC29, RxSPG_PropulsionCAN_PNC29], pnc-identifier=29, short-label=PNC29, vfc=[TopLevelComposition.Diagnostics, TopLevelComposition.VehicleDriving, TopLevelComposition.VehicleModeManagement]
        pnc-group=[TxSPG_PropulsionCAN_PNC30, RxSPG_PropulsionCAN_PNC30], pnc-identifier=30, short-label=PNC30, vfc=TopLevelComposition.GlobalShortDuration
        pnc-group=TxSPG_PropulsionCAN_PNC33, pnc-identifier=33, short-label=PNC33, vfc=TopLevelComposition.Brake
        pnc-group=[TxSPG_PropulsionCAN_PNC35, RxSPG_PropulsionCAN_PNC35], pnc-identifier=35, short-label=PNC35, vfc=TopLevelComposition.HVEnergyStorage
        pnc-group=[TxSPG_PropulsionCAN_PNC39, RxSPG_PropulsionCAN_PNC39], pnc-identifier=39, short-label=PNC39, vfc=TopLevelComposition.Crash
      sw-mappings:
        swc to ecu mapping IEMIEM: component=TopLevelComposition.IEM, ecu-instance=IEM
    root-software-compositions:
      root sw composition prototype TopLevelComposition: software-composition=TopLevelComposition
package /ECUExtractIEM/ComponentType
  composition sw component type TopLevelComposition
    13 x port group, all with category=PARTIAL_NETWORKING:
      ParkingDrivingClimatization: inner-group=IEM.ParkingDrivingClimatization
      Diagnostics: inner-group=IEM.Diagnostics
      VehicleDriving: inner-group=IEM.VehicleDriving
      VehicleModeManagement: inner-group=IEM.VehicleModeManagement
      TelematicsConnectivity: inner-group=IEM.TelematicsConnectivity
      HVEnergyStorage: inner-group=IEM.HVEnergyStorage
      Crash: inner-group=IEM.Crash
      InfotainmentPush: inner-group=IEM.InfotainmentPush
      PropulsionStart: inner-group=IEM.PropulsionStart
      GlobalShortDuration: inner-group=IEM.GlobalShortDuration
      Brake: inner-group=IEM.Brake
      ChargingHV: inner-group=IEM.ChargingHV
      Immobilizer: inner-group=IEM.Immobilizer
    component IEM: type=IEM
package /Communication/Pdu
  dcm i pdu IemToEtcUudtDcmIpdu{1..3}: length=8, diag-pdu-type=DIAG-RESPONSE
  dcm i pdu VgmToIemDiagDcmIpdu: length=4000, diag-pdu-type=DIAG-REQUEST
  dcm i pdu IemToVgmDiagDcmIpdu: length=4000, diag-pdu-type=DIAG-RESPONSE
  dcm i pdu VgmToAllFuncDiagDcmIpdu: length=6, diag-pdu-type=DIAG-REQUEST
  dcm i pdu EtcToAllJ1979OBDDiagDcmIpdu11: length=6, diag-pdu-type=DIAG-REQUEST
  dcm i pdu EtcToIemJ1979OBDDiagDcmIpdu11: length=4000, diag-pdu-type=DIAG-REQUEST
  dcm i pdu IemToEtcJ1979OBDDiagDcmIpdu11: length=4000, diag-pdu-type=DIAG-RESPONSE
package /Communication/ISignalGroup
  23 x i signal group:
    igImobEngChk2: i-signal=[isImobEngChk2ImobEngDataChk2, isImobEngChk2ImobEngDataChk3, isImobEngChk2ImobEngDataChk4, isImobEngChk2ImobEngDataChk6, isImobEngChk2ImobEngChkSts, isImobEngChk2ImobEngDataChk0, isImobEngChk2ImobEngDataChk5, isImobEngChk2ImobEngDataChk1], system-signal-group=ImobEngChk2
    igWhlMotSysTqAvl: i-signal=[isWhlMotSysTqAvlTqAvlMin, isWhlMotSysTqAvlTqAvlMax], system-signal-group=WhlMotSysTqAvl
    igWhlMotSysTqEst: i-signal=[isWhlMotSysTqEstCntr, isWhlMotSysTqEstIsgTqAct, isWhlMotSysTqEstQualityFactor, isWhlMotSysTqEstChks], system-signal-group=WhlMotSysTqEst
    igIemGeneric: i-signal=[isIemGenericFltAlrmSt, isIemGenericModStatusRms, isIemGenericIacAlrmSt, isIemGenericEMSeqNr, isIemGenericSpdAlrmSt, isIemGenericMotTAlrmSt, isIemGenericUDcAlrmSt, isIemGenericEMQnty, isIemGenericInvrtTAlrmSt, isIemGenericADAlrmSt, isIemGenericDTCHig, isIemGenericDTCLow, isIemGenericRslAlrmSt, isIemGenericDTCMid, isIemGenericDTCSts, isIemGenericTypeInfo], system-signal-group=IemGeneric
    igIEMTestFr2: i-signal=[isIEMTestFr2Byte2, isIEMTestFr2Byte3, isIEMTestFr2Byte5, isIEMTestFr2Byte7, isIEMTestFr2Byte6, isIEMTestFr2Byte4, isIEMTestFr2Byte1, isIEMTestFr2Byte0], system-signal-group=IEMTestFr2
    igIEMTestFr1: i-signal=[isIEMTestFr1Byte7, isIEMTestFr1Byte2, isIEMTestFr1Byte6, isIEMTestFr1Byte4, isIEMTestFr1Byte3, isIEMTestFr1Byte1, isIEMTestFr1Byte0, isIEMTestFr1Byte5], system-signal-group=IEMTestFr1
    igIEMTestFr3: i-signal=[isIEMTestFr3Byte0, isIEMTestFr3Byte4, isIEMTestFr3Byte5, isIEMTestFr3Byte6, isIEMTestFr3Byte1, isIEMTestFr3Byte7, isIEMTestFr3Byte2, isIEMTestFr3Byte3], system-signal-group=IEMTestFr3
    igWhlMotSysSpdActSafe: i-signal=[isWhlMotSysSpdActSafeChks, isWhlMotSysSpdActSafeIsgSpdWSgnTyp, isWhlMotSysSpdActSafeQf, isWhlMotSysSpdActSafeCntr], system-signal-group=WhlMotSysSpdActSafe
    igDmcStsRearToEsc: i-signal=[isDmcStsRearToEscDmcSts, isDmcStsRearToEscChks, isDmcStsRearToEscCntr, isDmcStsRearToEscDmcActAppTarTq, isDmcStsRearToEscDmcSWInfo], system-signal-group=DmcStsRearToEsc
    igStcStsToDmc: i-signal=[isStcStsToDmcEngRotTarSpdDMCFrnt, isStcStsToDmcFrnt, isStcStsToDmcEngRotTarSpdDMCRear, isStcStsToDmcChks, isStcStsToDmcCntr, isStcStsToDmcRear], system-signal-group=StcStsToDmc
    igCrashStsSafe: i-signal=[isCrashStsSafeCntr, isCrashStsSafeSts, isCrashStsSafeChks], system-signal-group=CrashStsSafe
    igVehMtnSt: i-signal=[isVehMtnStChks, isVehMtnStCntr, isVehMtnStVehMtnSt], system-signal-group=VehMtnSt
    igVehSpdLgt: i-signal=[isVehSpdLgtQf, isVehSpdLgtCntr, isVehSpdLgtChks, isVehSpdLgtA], system-signal-group=VehSpdLgt
    igVehModMngtGlbSafe1: i-signal=[isVehModMngtGlbSafe1Chks, isVehModMngtGlbSafe1CarModSts1, isVehModMngtGlbSafe1Cntr, isVehModMngtGlbSafe1EgyLvlElecSubtyp, isVehModMngtGlbSafe1PwrLvlElecSubtyp, isVehModMngtGlbSafe1CarModSubtypWdCarModSubtyp, isVehModMngtGlbSafe1UsgModSts, isVehModMngtGlbSafe1PwrLvlElecMai, isVehModMngtGlbSafe1EgyLvlElecMai, isVehModMngtGlbSafe1FltEgyCnsWdSts], system-signal-group=VehModMngtGlbSafe1
    igWhlMotSysTqAllwd: i-signal=[isWhlMotSysTqAllwdWhlMotSysTqAllwd, isWhlMotSysTqAllwdChks, isWhlMotSysTqAllwdCntr], system-signal-group=WhlMotSysTqAllwd
    igVehCfgPrm: i-signal=[isVehCfgPrmCCPBytePosn6, isVehCfgPrmBlkIDBytePosn1, isVehCfgPrmCCPBytePosn4, isVehCfgPrmCCPBytePosn3, isVehCfgPrmCCPBytePosn2, isVehCfgPrmCCPBytePosn8, isVehCfgPrmCCPBytePosn7, isVehCfgPrmCCPBytePosn5], system-signal-group=VehCfgPrm
    igEngSt1WdSts: i-signal=[isEngSt1WdStsChks, isEngSt1WdStsEngSt1WdSts, isEngSt1WdStsCntr], system-signal-group=EngSt1WdSts
    igImobEngMgrReq2: i-signal=[isImobEngMgrReq2ImobEngDataMgrReq4, isImobEngMgrReq2ImobEngMgrCmdTar1, isImobEngMgrReq2ImobEngDataMgrReq3, isImobEngMgrReq2ImobEngDataMgrReq2, isImobEngMgrReq2ImobEngDataMgrReq0, isImobEngMgrReq2ImobEngDataMgrReq5, isImobEngMgrReq2ImobEngDataMgrReq6, isImobEngMgrReq2ImobEngDataMgrReq1], system-signal-group=ImobEngMgrReq2
    igVehCfgPrmExt: i-signal=[isVehCfgPrmExtCCPBytePosn5, isVehCfgPrmExtCCPBytePosn6, isVehCfgPrmExtCCPBytePosn2, isVehCfgPrmExtCCPBytePosn3, isVehCfgPrmExtCCPBytePosn8, isVehCfgPrmExtCCPBytePosn4, isVehCfgPrmExtCCPBytePosn7, isVehCfgPrmExtBlkIDBytePosn1], system-signal-group=VehCfgPrmExt
    igPtTqAtAxleMaxReq: i-signal=[isPtTqAtAxleMaxReqChks, isPtTqAtAxleMaxReqPtTqAtAxleFrntReq, isPtTqAtAxleMaxReqCntr, isPtTqAtAxleMaxReqPtTqAtAxleReReq], system-signal-group=PtTqAtAxleMaxReq
    igVehBattU: i-signal=[isVehBattUSysU, isVehBattUSysUQf], system-signal-group=VehBattU
    igHvSysRlySts: i-signal=[isHvSysRlyStsChks, isHvSysRlyStsHvSysRlySts, isHvSysRlyStsCntr], system-signal-group=HvSysRlySts
    igEscVariantToDmc: i-signal=[isEscVariantToDmcChks, isEscVariantToDmcEscVariantToDmc, isEscVariantToDmcCntr], system-signal-group=EscVariantToDmc
package /Communication/ISignalPduGroup
  22 x i signal i pdu group:
    TxMPG_PropulsionCAN: communication-direction=OUT, communication-mode=tx, contained-i-signal-i-pdu-group=[TxSPG_PropulsionCAN_PNC30, TxSPG_PropulsionCAN_PNC16, TxSPG_PropulsionCAN_PNC29, TxSPG_PropulsionCAN_PNC27, TxSPG_PropulsionCAN, TxSPG_PropulsionCAN_PNC39, TxSPG_PropulsionCAN_PNC24, TxSPG_PropulsionCAN_PNC26, TxSPG_PropulsionCAN_PNC33, TxSPG_PropulsionCAN_PNC35, TxSPG_PropulsionCAN_PNC25]
    TxSPG_PropulsionCAN_PNC30: communication-direction=OUT, communication-mode=tx, i-signal-i-pdus=[IemPropSignalIPdu12, IemEduPropSignalIPdu01]
    TxSPG_PropulsionCAN_PNC16: communication-direction=OUT, communication-mode=tx, i-signal-i-pdus=[IemPropSignalIPdu12, IemPropSignalIPdu08, IemEduPropSignalIPdu01]
    TxSPG_PropulsionCAN_PNC29: communication-direction=OUT, communication-mode=tx
      i-signal-i-pdus:
        IemPropSignalIPdu07
        IemPropSignalIPdu03
        IemPropSignalIPdu06
        IemPropSignalIPdu14
        IemPropSignalIPdu04
        IemPropSignalIPdu12
        IemPropSignalIPdu08
        IemEduPropSignalIPdu01
    TxSPG_PropulsionCAN_PNC27: communication-direction=OUT, communication-mode=tx, i-signal-i-pdus=[IemPropSignalIPdu03, IemPropSignalIPdu06, IemPropSignalIPdu08, IemEduPropSignalIPdu01]
    TxSPG_PropulsionCAN: communication-direction=OUT, communication-mode=tx, i-signal-i-pdus=[IemEduPropSignalIPdu02, IemPropSignalIPdu02, IemPropSignalIPdu09, IemPropSignalIPdu16, IemPropSignalIPdu01]
    TxSPG_PropulsionCAN_PNC39: communication-direction=OUT, communication-mode=tx, i-signal-i-pdus=[IemPropSignalIPdu07, IemPropSignalIPdu03, IemPropSignalIPdu12, IemPropSignalIPdu08, IemEduPropSignalIPdu01]
    TxSPG_PropulsionCAN_PNC24: communication-direction=OUT, communication-mode=tx
      i-signal-i-pdus:
        IemPropSignalIPdu07
        IemPropSignalIPdu03
        IemPropSignalIPdu06
        IemPropSignalIPdu14
        IemPropSignalIPdu04
        IemPropSignalIPdu08
        IemEduPropSignalIPdu01
    TxSPG_PropulsionCAN_PNC26: communication-direction=OUT, communication-mode=tx
      i-signal-i-pdus:
        IemPropSignalIPdu07
        IemPropSignalIPdu03
        IemPropSignalIPdu06
        IemPropSignalIPdu14
        IemPropSignalIPdu04
        IemPropSignalIPdu08
        IemEduPropSignalIPdu01
    TxSPG_PropulsionCAN_PNC33: communication-direction=OUT, communication-mode=tx, i-signal-i-pdus=[IemPropSignalIPdu12, IemPropSignalIPdu08, IemEduPropSignalIPdu01]
    TxSPG_PropulsionCAN_PNC35: communication-direction=OUT, communication-mode=tx, i-signal-i-pdus=[IemPropSignalIPdu07, IemPropSignalIPdu03, IemPropSignalIPdu08, IemEduPropSignalIPdu01]
    TxSPG_PropulsionCAN_PNC25: communication-direction=OUT, communication-mode=tx
      i-signal-i-pdus:
        IemPropSignalIPdu07
        IemPropSignalIPdu03
        IemPropSignalIPdu06
        IemPropSignalIPdu14
        IemPropSignalIPdu12
        IemPropSignalIPdu08
        IemEduPropSignalIPdu01
    RxMPG_PropulsionCAN: communication-direction=IN, communication-mode=rx, contained-i-signal-i-pdu-group=[RxSPG_PropulsionCAN_PNC27, RxSPG_PropulsionCAN_PNC24, RxSPG_PropulsionCAN_PNC26, RxSPG_PropulsionCAN_PNC39, RxSPG_PropulsionCAN_PNC25, RxSPG_PropulsionCAN_PNC30, RxSPG_PropulsionCAN, RxSPG_PropulsionCAN_PNC29, RxSPG_PropulsionCAN_PNC35]
    RxSPG_PropulsionCAN_PNC27: communication-direction=IN, communication-mode=rx, i-signal-i-pdus=CddObcPropSignalIPdu01
    RxSPG_PropulsionCAN_PNC24: communication-direction=IN, communication-mode=rx
      i-signal-i-pdus:
        BecmPropSignalIpdu03
        BecmPropSignalIpdu15
        EcmPropSignalIPDU08
        EcmPropSignalIPdu24
        BecmPropSignalIpdu02
        EcmPropSignalIPdu25
        VDDMPropSignalIPDU16
        ECMPropSignalIPDU06
        BecmPropSignalIpdu01
        ECMPropSignalIPDU05
        ECMPropSignalIPDU04
        CddObcPropSignalIPdu01
        ECMPropSignalIPDU02
    RxSPG_PropulsionCAN_PNC26: communication-direction=IN, communication-mode=rx
      i-signal-i-pdus:
        SrsPropSignalIPdu02
        BecmPropSignalIpdu03
        BecmPropSignalIpdu15
        EcmPropSignalIPDU08
        EcmPropSignalIPdu24
        EcmPropSignalIPDU28
        VDDMPropSignalIPDU11
        VDDMPropSignalIPDU05
        BecmPropSignalIpdu02
        EcmPropSignalIPdu25
        VDDMPropSignalIPDU16
        EcmPropSignalIPDU11
        ECMPropSignalIPDU06
        BecmPropSignalIpdu01
        ECMPropSignalIPDU05
        ECMPropSignalIPDU04
        CddObcPropSignalIPdu01
        ECMPropSignalIPDU02
    RxSPG_PropulsionCAN_PNC39: communication-direction=IN, communication-mode=rx
      i-signal-i-pdus:
        EcmPropSignalIPdu25
        SrsPropSignalIPdu02
        BecmPropSignalIpdu03
        EcmPropSignalIPDU11
        BecmPropSignalIpdu15
        BecmPropSignalIpdu01
        VDDMPropSignalIPDU08
        BecmPropSignalIpdu02
    RxSPG_PropulsionCAN_PNC25: communication-direction=IN, communication-mode=rx
      i-signal-i-pdus:
        EcmPropSignalIPdu25
        BecmPropSignalIpdu03
        BecmPropSignalIpdu15
        ECMPropSignalIPDU06
        EcmPropSignalIPDU08
        BecmPropSignalIpdu01
        ECMPropSignalIPDU05
        EcmPropSignalIPdu24
        ECMPropSignalIPDU04
        CddObcPropSignalIPdu01
        ECMPropSignalIPDU02
        BecmPropSignalIpdu02
    RxSPG_PropulsionCAN_PNC30: communication-direction=IN, communication-mode=rx
      i-signal-i-pdus:
        SrsPropSignalIPdu02
        BecmPropSignalIpdu03
        BecmPropSignalIpdu15
        BecmPropSignalIpdu01
        CddObcPropSignalIPdu01
        VDDMPropSignalIPDU11
        VDDMPropSignalIPDU05
        BecmPropSignalIpdu02
    RxSPG_PropulsionCAN: communication-direction=IN, communication-mode=rx
      i-signal-i-pdus:
        VddmPropSignalIPdu26
        VDDMPropSignalIPDU17
        VDDMPropSignalIPDU19
        VddmBcmPropdTCSignalIPDU01
        VDDMPropSignalIPDU18
        VDDMPropSignalIPDU06
        VDDMPropdTCSignalIPdu38
    RxSPG_PropulsionCAN_PNC29: communication-direction=IN, communication-mode=rx
      i-signal-i-pdus:
        SrsPropSignalIPdu02
        BecmPropSignalIpdu03
        BecmPropSignalIpdu15
        EcmPropSignalIPDU08
        VDDMPropSignalIPDU08
        EcmPropSignalIPdu24
        EcmPropSignalIPDU28
        VDDMPropSignalIPDU11
        VDDMPropSignalIPDU05
        BecmPropSignalIpdu02
        EcmPropSignalIPdu25
        VDDMPropSignalIPDU16
        EcmPropSignalIPDU11
        ECMPropSignalIPDU06
        BecmPropSignalIpdu01
        ECMPropSignalIPDU05
        ECMPropSignalIPDU04
        CddObcPropSignalIPdu01
        ECMPropSignalIPDU02
    RxSPG_PropulsionCAN_PNC35: communication-direction=IN, communication-mode=rx
      i-signal-i-pdus:
        BecmPropSignalIpdu03
        EcmPropSignalIPDU11
        BecmPropSignalIpdu15
        EcmPropSignalIPDU08
        BecmPropSignalIpdu01
        BecmPropSignalIpdu02
package /Communication/NmConfig
  nm config NmConfigxMA1: can-nm-cluster-coupling{coupled-cluster=PropulsionCanNmCluster, nm-busload-reduction-enabled=false, nm-immediate-restart-enabled=false}
    can nm cluster PropulsionCanNmCluster:
      communication-cluster=PropulsionCAN
      nm-channel-id=8
      nm-channel-sleep-master=false
      nm-synchronizing-network=false
      nm-busload-reduction-active=false
      nm-car-wake-up-rx-enabled=false
      nm-cbv-position=1
      nm-channel-active=true
      nm-immediate-nm-cycle-time=0.02
      nm-immediate-nm-transmissions=20
      nm-message-timeout-time=0.5
      nm-msg-cycle-time=1
      nm-network-timeout=3
      nm-nid-position=0
      nm-remote-sleep-indication-time=0
      nm-repeat-message-time=1
      nm-user-data-length=6
      nm-wait-bus-sleep-time=4
      can nm node IemPropCanNmNode: controller=PropulsionCAN, nm-if-ecu=IemNmEcu, nm-node-id=28, rx-nm-pdu=IgmPropNmPdu1, tx-nm-pdu=IemPropNmPdu1, nm-msg-cycle-offset=0.1, nm-msg-reduced-time=0.5, nm-range-config={lower-can-id=1280, upper-can-id=1343}
    nm-if-ecus:
      nm ecu IemNmEcu:
        bus-specific-nm-ecu=can-nm-ecu=nm-repeat-msg-indication-enabled=false
        ecu-instance=IEM
        nm-bus-synchronization-enabled=false
        nm-com-control-enabled=false
        nm-cycletime-main-function=0.005
        nm-node-detection-enabled=true
        nm-node-id-enabled=true
        nm-passive-mode-enabled=false
        nm-pdu-rx-indication-enabled=true
        nm-remote-sleep-ind-enabled=false
        nm-repeat-msg-ind-enabled=false
        nm-state-change-ind-enabled=false
        nm-user-data-enabled=true
package /Communication/TpConfig
  can tp config UudtPropCanTpConfig1: communication-cluster=PropulsionCAN, can-tp-ecu{cycle-time-main-function=0.005, ecu-instance=IEM}
    can tp address IemPropCanTpAddr: tp-address=55
    can tp address EtcPropCanTpAddr: tp-address=128
    can tp channel IemEtcUUDTPropCha1: channel-id=48, channel-mode=HALF-DUPLEX-MODE
    can tp channel IemEtcUUDTPropCha2: channel-id=49, channel-mode=HALF-DUPLEX-MODE
    can tp channel IemEtcUUDTPropCha3: channel-id=50, channel-mode=HALF-DUPLEX-MODE
    tp-connections:
      addressing-format=STANDARD, can-tp-channel=IemEtcUUDTPropCha{1..3}, cancellation=false, data-pdu=UudtIemNPdu{1..3}, max-block-size=0, padding-activation=true, receiver=EtcPropUUDTTpNode, timeout-br=0.9, timeout-bs=1, timeout-cr=1, timeout-cs=0.9, tp-sdu=IemToEtcUudtDcmIpdu{1..3}, transmit-cancellation=false, transmitter=UudtPropCanTpConfig1/IemPropCanTpNode
    can tp node IemPropCanTpNode: connector=PropulsionCAN_IEM, st-min=0.005, timeout-as=1, tp-address=UudtPropCanTpConfig1/IemPropCanTpAddr
    can tp node EtcPropUUDTTpNode: max-fc-wait=255, timeout-ar=1, tp-address=UudtPropCanTpConfig1/EtcPropCanTpAddr
  can tp config PropCanTpConfig1: communication-cluster=PropulsionCAN, can-tp-ecu{cycle-time-main-function=0.005, ecu-instance=IEM}
    20 x can tp address:
      EtcPropCanTpAddr: tp-address=128
      IemPropCanTpAddr: tp-address=55
      VddmToAllPropCanTpAddr: tp-address=255
      EcmPropCanTpAddr: tp-address=48
      TcmPropCanTpAddr: tp-address=50
      ObcPropCanTpAddr: tp-address=52
      BecmPropCanTpAddr: tp-address=53
      IgmPropCanTpAddr: tp-address=54
      DemPropCanTpAddr: tp-address=56
      EgsmPropCanTpAddr: tp-address=51
      EsmPropCanTpAddr: tp-address=58
      TacmPropCanTpAddr: tp-address=60
      IsgmPropCanTpAddr: tp-address=62
      MvbmPropCanTpAddr: tp-address=82
      MvcmPropCanTpAddr: tp-address=61
      CddPropCanTpAddr: tp-address=80
      MgmPropCanTpAddr: tp-address=49
      MvemPropCanTpAddr: tp-address=81
      SpnsPropCanTpAddr: tp-address=84
      HvcmPropCanTpAddr: tp-address=85
    can tp channel VddmIemPropDiagCha: channel-id=23, channel-mode=HALF-DUPLEX-MODE
    can tp channel VddmToAllFuncPropDiagCha: channel-id=16, channel-mode=HALF-DUPLEX-MODE
    tp-connections:
      addressing-format=STANDARD, can-tp-channel=VddmIemPropDiagCha, cancellation=false, data-pdu=VddmToIemPropDiagReqNpdu, flow-control-pdu=IemToVddmPropDiagResNpdu, max-block-size=0, padding-activation=true, receiver=PropCanTpConfig1/IemPropCanTpNode, timeout-br=0.9, timeout-bs=1, timeout-cr=1, timeout-cs=0.9, tp-sdu=VgmToIemDiagDcmIpdu, transmit-cancellation=false, transmitter=VddmPropCanTpNode
      addressing-format=STANDARD, can-tp-channel=VddmIemPropDiagCha, cancellation=false, data-pdu=IemToVddmPropDiagResNpdu, flow-control-pdu=VddmToIemPropDiagReqNpdu, max-block-size=0, padding-activation=true, receiver=VddmPropCanTpNode, timeout-br=0.9, timeout-bs=1, timeout-cr=1, timeout-cs=0.9, tp-sdu=IemToVgmDiagDcmIpdu, transmit-cancellation=false, transmitter=PropCanTpConfig1/IemPropCanTpNode
      addressing-format=STANDARD, can-tp-channel=VddmToAllFuncPropDiagCha, cancellation=false, data-pdu=VddmToAllFuncPropDiagReqNpdu, max-block-size=0, multicast=VddmToAllPropCanTpAddr, padding-activation=true, receiver=[EcmPropCanTpNode, TcmPropCanTpNode, ObcPropCanTpNode, BecmPropCanTpNode, IgmPropCanTpNode, PropCanTpConfig1/IemPropCanTpNode, DemPropCanTpNode, EgsmPropCanTpNode, EsmPropCanTpNode, TacmPropCanTpNode, IsgmPropCanTpNode, MvbmPropCanTpNode, MvcmPropCanTpNode, CddPropCanTpNode, MgmPropCanTpNode, MvemPropCanTpNode, SpnsPropCanTpNode, HvcmPropCanTpNode], timeout-br=0.9, timeout-bs=1, timeout-cr=1, timeout-cs=0.9, tp-sdu=VgmToAllFuncDiagDcmIpdu, transmit-cancellation=false, transmitter=VddmPropCanTpNode
    19 x can tp node, all with max-fc-wait=255, timeout-ar=1:
      VddmPropCanTpNode: st-min=0.005, timeout-as=1, tp-address=PropCanTpConfig1/EtcPropCanTpAddr
      IemPropCanTpNode: connector=PropulsionCAN_IEM, st-min=0.005, timeout-as=1, tp-address=PropCanTpConfig1/IemPropCanTpAddr
      EcmPropCanTpNode: tp-address=EcmPropCanTpAddr
      TcmPropCanTpNode: tp-address=TcmPropCanTpAddr
      ObcPropCanTpNode: tp-address=ObcPropCanTpAddr
      BecmPropCanTpNode: tp-address=BecmPropCanTpAddr
      IgmPropCanTpNode: tp-address=IgmPropCanTpAddr
      DemPropCanTpNode: tp-address=DemPropCanTpAddr
      EgsmPropCanTpNode: tp-address=EgsmPropCanTpAddr
      EsmPropCanTpNode: tp-address=EsmPropCanTpAddr
      TacmPropCanTpNode: tp-address=TacmPropCanTpAddr
      IsgmPropCanTpNode: tp-address=IsgmPropCanTpAddr
      MvbmPropCanTpNode: tp-address=MvbmPropCanTpAddr
      MvcmPropCanTpNode: tp-address=MvcmPropCanTpAddr
      CddPropCanTpNode: tp-address=CddPropCanTpAddr
      MgmPropCanTpNode: tp-address=MgmPropCanTpAddr
      MvemPropCanTpNode: tp-address=MvemPropCanTpAddr
      SpnsPropCanTpNode: tp-address=SpnsPropCanTpAddr
      HvcmPropCanTpNode: tp-address=HvcmPropCanTpAddr
  can tp config J1979OBDPropCanTpConfig11: communication-cluster=PropulsionCAN, can-tp-ecu{cycle-time-main-function=0.005, ecu-instance=IEM}
    14 x can tp address:
      VgmToAllFuncCarbPropCanTpAddr: tp-address=223
      VgmPropCanTpAddr: tp-address=128
      VddmCarbPropCanTpAddr: tp-address=230
      BecmCarbPropCanTpAddr: tp-address=226
      EcmCarbPropCanTpAddr: tp-address=224
      IemCarbPropCanTpAddr: tp-address=227
      IgmCarbPropCanTpAddr: tp-address=228
      ObcCarbPropCanTpAddr: tp-address=229
      MvemCarbPropCanTpAddr: tp-address=227
      TcmCarbPropCanTpAddr: tp-address=225
      CddCarbPropCanTpAddr: tp-address=229
      IsgmCarbPropCanTpAddr: tp-address=228
      MgmCarbPropCanTpAddr: tp-address=228
      MvbmCarbPropCanTpAddr: tp-address=226
    can tp channel VgmToAllJ1979OBDDiagCha11: channel-id=8, channel-mode=HALF-DUPLEX-MODE
    can tp channel VgmIemJ1979OBDDiagCha11: channel-id=3, channel-mode=HALF-DUPLEX-MODE
    tp-connections:
      addressing-format=STANDARD, can-tp-channel=VgmToAllJ1979OBDDiagCha11, cancellation=false, data-pdu=VgmToAllFuncJ1979OBDPropCanReqNpdu11, max-block-size=0, multicast=VgmToAllFuncCarbPropCanTpAddr, padding-activation=true, receiver=[VddmCarbPropCanTpNode, BecmCarbPropCanTpNode, EcmCarbPropCanTpNode, IemCarbPropCanTpNode, IgmCarbPropCanTpNode, ObcCarbPropCanTpNode, MvemCarbPropCanTpNode, TcmCarbPropCanTpNode, CddCarbPropCanTpNode, IsgmCarbPropCanTpNode, MgmCarbPropCanTpNode, MvbmCarbPropCanTpNode], timeout-br=0.9, timeout-bs=1, timeout-cr=1, timeout-cs=0.9, tp-sdu=EtcToAllJ1979OBDDiagDcmIpdu11, transmit-cancellation=false, transmitter=VgmCarbPropCanTpNode
      addressing-format=STANDARD, can-tp-channel=VgmIemJ1979OBDDiagCha11, cancellation=false, data-pdu=VgmToIemJ1979OBDPropCanReqNpdu11, flow-control-pdu=IemToVgmJ1979OBDPropCanResNpdu11, max-block-size=0, padding-activation=true, receiver=IemCarbPropCanTpNode, timeout-br=0.9, timeout-bs=1, timeout-cr=1, timeout-cs=0.9, tp-sdu=EtcToIemJ1979OBDDiagDcmIpdu11, transmit-cancellation=false, transmitter=VgmCarbPropCanTpNode
      addressing-format=STANDARD, can-tp-channel=VgmIemJ1979OBDDiagCha11, cancellation=false, data-pdu=IemToVgmJ1979OBDPropCanResNpdu11, flow-control-pdu=VgmToIemJ1979OBDPropCanReqNpdu11, max-block-size=0, padding-activation=true, receiver=VgmCarbPropCanTpNode, timeout-br=0.9, timeout-bs=1, timeout-cr=1, timeout-cs=0.9, tp-sdu=IemToEtcJ1979OBDDiagDcmIpdu11, transmit-cancellation=false, transmitter=IemCarbPropCanTpNode
    13 x can tp node, all with max-fc-wait=255, timeout-ar=1:
      VgmCarbPropCanTpNode: st-min=0.005, timeout-as=1, tp-address=VgmPropCanTpAddr
      VddmCarbPropCanTpNode: tp-address=VddmCarbPropCanTpAddr
      BecmCarbPropCanTpNode: tp-address=BecmCarbPropCanTpAddr
      EcmCarbPropCanTpNode: tp-address=EcmCarbPropCanTpAddr
      IemCarbPropCanTpNode: connector=PropulsionCAN_IEM, st-min=0.005, timeout-as=1, tp-address=IemCarbPropCanTpAddr
      IgmCarbPropCanTpNode: tp-address=IgmCarbPropCanTpAddr
      ObcCarbPropCanTpNode: tp-address=ObcCarbPropCanTpAddr
      MvemCarbPropCanTpNode: tp-address=MvemCarbPropCanTpAddr
      TcmCarbPropCanTpNode: tp-address=TcmCarbPropCanTpAddr
      CddCarbPropCanTpNode: tp-address=CddCarbPropCanTpAddr
      IsgmCarbPropCanTpNode: tp-address=IsgmCarbPropCanTpAddr
      MgmCarbPropCanTpNode: tp-address=MgmCarbPropCanTpAddr
      MvbmCarbPropCanTpNode: tp-address=MvbmCarbPropCanTpAddr
